// *************************************************************************** *
// *                                                                           *
// * Description:         CANDB File                                           *
// * Generated at:        2023-01-05 13:51                                     *
// * System:              FLRsystem_MAIN_26                                    *
// * Network:             FLR1CAN                                              *
// *                                                                           *
// *************************************************************************** *
VERSION "FLR1CAN"

NS_ :

BS_ :

BU_ :  FLR FLRdpHPA FLRdpHPB

BO_ 1794 Flr1canTimeSyncFr01 : 8 FLRdpHPA

BO_ 512 FlrdpFlr1canFr02 : 48 FLRdpHPA
 SG_ VehicleMotionState_UB : 280|1@0+ (1,0) [0|1] "" FLR
 SG_ VehicleMotionStateAcceleroMeterLateral : 24|15@1+ (0.0085,-138.992) [-138.992|139.00050000000002] "m/s^2" FLR
 SG_ VehicleMotionStateAccelerometerLateralQuality : 232|3@1+ (1,0) [0|7] "" FLR
 SG_ VehicleMotionStateAccelerometerLongitudinal : 40|15@1+ (0.0085,-138.992) [-138.992|139.00050000000002] "m/s^2" FLR
 SG_ VehicleMotionStateAccelerometerLongitudinalQuality : 235|3@1+ (1,0) [0|7] "" FLR
 SG_ VehicleMotionStateAccelerometerVertical : 56|15@1+ (0.0085,-138.992) [-138.992|139.00050000000002] "m/s^2" FLR
 SG_ VehicleMotionStateAccelerometerVerticalQuality : 240|3@1+ (1,0) [0|7] "" FLR
 SG_ VehicleMotionStateAngularVelocityRoll : 72|16@1+ (0.000159791,-5.236031488) [-5.236031488|5.235871697] "rad/s" FLR
 SG_ VehicleMotionStateAngularVelocityRollQuality : 243|3@1+ (1,0) [0|7] "" FLR
 SG_ VehicleMotionStateAngularVelocityYaw : 104|16@1+ (0.000159791,-5.236031488) [-5.236031488|5.235871697] "rad/s" FLR
 SG_ VehicleMotionStateAngularVelocityYawQuality : 248|3@1+ (1,0) [0|7] "" FLR
 SG_ VehicleMotionStateCounter : 16|8@1+ (1.0,0.0) [0.0|255.0] "Unitless" FLR
 SG_ VehicleMotionStateCRC : 0|16@1+ (1.0,0.0) [0.0|65535.0] "Unitless" FLR
 SG_ VehicleMotionStateMovingDirection : 251|3@1+ (1,0) [0|7] "" FLR
 SG_ VehicleMotionStateMovingDirectionQuality : 256|3@1+ (1,0) [0|7] "" FLR
 SG_ VehicleMotionStateVelocityLongitudinal : 152|13@1- (0.02,0.0) [-81.9|81.9] "m/s" FLR
 SG_ VehicleMotionStateVelocityLongitudinalQuality : 128|3@1+ (1,0) [0|7] "" FLR
 SG_ VehicleMotionStateWheelAngle : 136|15@1+ (0.00005249,-0.85) [-0.85|0.8500461200000001] "rad" FLR
 SG_ VehicleMotionStateWheelAngleQuality : 131|3@1+ (1,0) [0|7] "" FLR
 SG_ VehicleMotionStateWheelAngularVelocityFrontLeft : 168|16@1+ (0.0078125,-255.0) [-255.0|255.0] "rad/s" FLR
 SG_ VehicleMotionStateWheelAngularVelocityFrontLeftQuality : 264|3@1+ (1,0) [0|7] "" FLR
 SG_ VehicleMotionStateWheelAngularVelocityFrontRight : 184|16@1+ (0.0078125,-255.0) [-255.0|255.0] "rad/s" FLR
 SG_ VehicleMotionStateWheelAngularVelocityFrontRightQuality : 267|3@1+ (1,0) [0|7] "" FLR
 SG_ VehicleMotionStateWheelAngularVelocityRearLeft : 200|16@1+ (0.0078125,-255.0) [-255.0|255.0] "rad/s" FLR
 SG_ VehicleMotionStateWheelAngularVelocityRearLeftQuality : 272|3@1+ (1,0) [0|7] "" FLR
 SG_ VehicleMotionStateWheelAngularVelocityRearRight : 216|16@1+ (0.0078125,-255.0) [-255.0|255.0] "rad/s" FLR
 SG_ VehicleMotionStateWheelAngularVelocityRearRightQuality : 275|3@1+ (1,0) [0|7] "" FLR

BO_ 528 FlrdpFlr1canFr03 : 12 FLRdpHPA
 SG_ CarConfig_UB : 72|1@0+ (1,0) [0|1] "" FLR
 SG_ CarConfigCounter : 16|8@1+ (1.0,0.0) [0.0|255.0] "Unitless" FLR
 SG_ CarConfigCRC : 0|16@1+ (1.0,0.0) [0.0|65535.0] "Unitless" FLR
 SG_ CarConfigPropulsionType : 24|2@1+ (1,0) [0|3] "" FLR
 SG_ CarConfigVehicleTyp : 27|8@1+ (1,0) [0|255] "" FLR
 SG_ PowerModeFLR_UB : 73|1@0+ (1,0) [0|1] "" FLR
 SG_ PowerModeFLRCounter : 56|8@1+ (1.0,0.0) [0.0|255.0] "Unitless" FLR
 SG_ PowerModeFLRCRC : 40|16@1+ (1.0,0.0) [0.0|65535.0] "Unitless" FLR
 SG_ PowerModeFLRRdrActvnReq : 64|1@1+ (1,0) [0|1] "" FLR
 SG_ PowerModeFLRRdrPwrlossNoti : 65|1@1+ (1,0) [0|1] "" FLR

BO_ 544 FlrdpFlr1canFr04 : 32 FLRdpHPA
 SG_ GlobalSnapShotRdr_UB : 128|1@0+ (1,0) [0|1] "" FLR
 SG_ GlobalSnapShotRdrCounter : 16|8@1+ (1.0,0.0) [0.0|255.0] "Unitless" FLR
 SG_ GlobalSnapShotRdrCRC : 0|16@1+ (1.0,0.0) [0.0|65535.0] "Unitless" FLR
 SG_ GlobalSnapShotRdrGlobalRealTimeRdr : 24|32@1+ (1.0,0.0) [0.0|4294967295.0] "s" FLR
 SG_ GlobalSnapShotRdrOutsideTemperatureRdr : 56|16@1- (0.1,0.0) [-3276.8|3276.7000000000003] "degC" FLR
 SG_ GlobalSnapShotRdrTotalDistanceRdr : 72|32@1+ (1.0,0.0) [0.0|4294967295.0] "km" FLR
 SG_ GlobalSnapShotRdrUsageModeRdr : 104|8@1+ (1.0,0.0) [0.0|255.0] "Unitless" FLR
 SG_ GlobalSnapShotRdrVehicleBatteryVoltageRdr : 112|8@1+ (0.25,0.0) [0.0|63.75] "Volt" FLR
 SG_ GlobalSnapShotRdrVehicleSpeedRdr : 120|8@1+ (1.0,0.0) [0.0|255.0] "Km/h" FLR

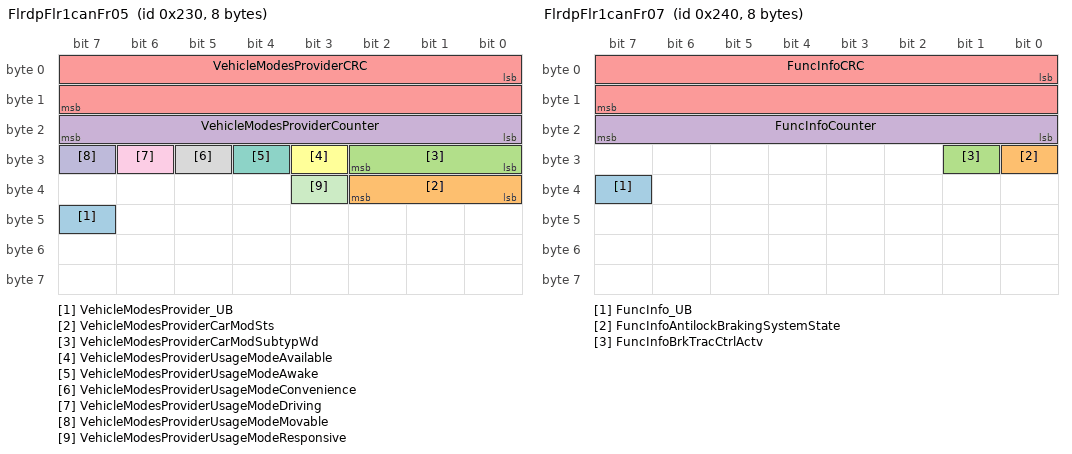
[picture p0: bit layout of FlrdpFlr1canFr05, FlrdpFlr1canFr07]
BO_ 560 FlrdpFlr1canFr05 : 8 FLRdpHPA
 SG_ VehicleModesProvider_UB : 47|1@0+ (1,0) [0|1] "" FLR
 SG_ VehicleModesProviderCarModSts : 32|3@1+ (1,0) [0|7] "" FLR
 SG_ VehicleModesProviderCarModSubtypWd : 24|3@1+ (1,0) [0|7] "" FLR
 SG_ VehicleModesProviderCounter : 16|8@1+ (1.0,0.0) [0.0|255.0] "Unitless" FLR
 SG_ VehicleModesProviderCRC : 0|16@1+ (1.0,0.0) [0.0|65535.0] "Unitless" FLR
 SG_ VehicleModesProviderUsageModeAvailable : 27|1@1+ (1,0) [0|1] "" FLR
 SG_ VehicleModesProviderUsageModeAwake : 28|1@1+ (1,0) [0|1] "" FLR
 SG_ VehicleModesProviderUsageModeConvenience : 29|1@1+ (1,0) [0|1] "" FLR
 SG_ VehicleModesProviderUsageModeDriving : 30|1@1+ (1,0) [0|1] "" FLR
 SG_ VehicleModesProviderUsageModeMovable : 31|1@1+ (1,0) [0|1] "" FLR
 SG_ VehicleModesProviderUsageModeResponsive : 35|1@1+ (1,0) [0|1] "" FLR

BO_ 576 FlrdpFlr1canFr07 : 8 FLRdpHPA
 SG_ FuncInfo_UB : 39|1@0+ (1,0) [0|1] "" FLR
 SG_ FuncInfoAntilockBrakingSystemState : 24|1@1+ (1,0) [0|1] "" FLR
 SG_ FuncInfoBrkTracCtrlActv : 25|1@1+ (1,0) [0|1] "" FLR
 SG_ FuncInfoCounter : 16|8@1+ (1.0,0.0) [0.0|255.0] "Unitless" FLR
 SG_ FuncInfoCRC : 0|16@1+ (1.0,0.0) [0.0|65535.0] "Unitless" FLR

BO_ 320 FlrFlr1canFr81 : 64 FLR
 SG_ FLR2RdrObject0To1_UB : 367|1@0+ (1,0) [0|1] "" FLRdpHPA,FLRdpHPB
 SG_ FLR2RdrObject0To1Class0 : 36|2@1+ (1,0) [0|3] "" FLRdpHPA,FLRdpHPB
 SG_ FLR2RdrObject0To1Class1 : 195|2@1+ (1,0) [0|3] "" FLRdpHPA,FLRdpHPB
 SG_ FLR2RdrObject0To1Counter : 16|8@1+ (1.0,0.0) [0.0|255.0] "Unitless" FLRdpHPA,FLRdpHPB
 SG_ FLR2RdrObject0To1CRC : 0|16@1+ (1.0,0.0) [0.0|65535.0] "Unitless" FLRdpHPA,FLRdpHPB
 SG_ FLR2RdrObject0To1DataCoastCntr0 : 38|3@1+ (1,0) [0|7] "" FLRdpHPA,FLRdpHPB
 SG_ FLR2RdrObject0To1DataCoastCntr1 : 197|3@1+ (1,0) [0|7] "" FLRdpHPA,FLRdpHPB
 SG_ FLR2RdrObject0To1DataConf0 : 41|7@1+ (1.0,0.0) [0.0|100.0] "%" FLRdpHPA,FLRdpHPB
 SG_ FLR2RdrObject0To1DataConf1 : 200|7@1+ (1.0,0.0) [0.0|100.0] "%" FLRdpHPA,FLRdpHPB
 SG_ FLR2RdrObject0To1DataLen0 : 48|8@1+ (0.2,0.0) [0.0|30.0] "m" FLRdpHPA,FLRdpHPB
 SG_ FLR2RdrObject0To1DataLen1 : 207|8@1+ (0.2,0.0) [0.0|30.0] "m" FLRdpHPA,FLRdpHPB
 SG_ FLR2RdrObject0To1DataStDLatAcc0 : 56|5@1+ (0.35,0.0) [0.0|10.85] "m/s^2" FLRdpHPA,FLRdpHPB
 SG_ FLR2RdrObject0To1DataStDLatAcc1 : 215|5@1+ (0.35,0.0) [0.0|10.85] "m/s^2" FLRdpHPA,FLRdpHPB
 SG_ FLR2RdrObject0To1DataStDLatPos0 : 61|8@1+ (0.1,0.0) [0.0|25.5] "m" FLRdpHPA,FLRdpHPB
 SG_ FLR2RdrObject0To1DataStDLatPos1 : 220|8@1+ (0.1,0.0) [0.0|25.5] "m" FLRdpHPA,FLRdpHPB
 SG_ FLR2RdrObject0To1DataStDLatVelo0 : 69|6@1+ (0.2,0.0) [0.0|12.600000000000001] "m/s" FLRdpHPA,FLRdpHPB
 SG_ FLR2RdrObject0To1DataStDLatVelo1 : 228|6@1+ (0.2,0.0) [0.0|12.600000000000001] "m/s" FLRdpHPA,FLRdpHPB
 SG_ FLR2RdrObject0To1DataStDLgtAcc0 : 75|5@1+ (0.35,0.0) [0.0|10.85] "m/s^2" FLRdpHPA,FLRdpHPB
 SG_ FLR2RdrObject0To1DataStDLgtAcc1 : 234|5@1+ (0.35,0.0) [0.0|10.85] "m/s^2" FLRdpHPA,FLRdpHPB
 SG_ FLR2RdrObject0To1DataStDLgtPos0 : 80|8@1+ (0.05,0.0) [0.0|12.75] "m" FLRdpHPA,FLRdpHPB
 SG_ FLR2RdrObject0To1DataStDLgtPos1 : 239|8@1+ (0.05,0.0) [0.0|12.75] "m" FLRdpHPA,FLRdpHPB
 SG_ FLR2RdrObject0To1DataStDLgtVelo0 : 88|6@1+ (0.2,0.0) [0.0|12.600000000000001] "m/s" FLRdpHPA,FLRdpHPB
 SG_ FLR2RdrObject0To1DataStDLgtVelo1 : 247|6@1+ (0.2,0.0) [0.0|12.600000000000001] "m/s" FLRdpHPA,FLRdpHPB
 SG_ FLR2RdrObject0To1DataWidth0 : 94|7@1+ (0.2,0.0) [0.0|15.0] "m" FLRdpHPA,FLRdpHPB
 SG_ FLR2RdrObject0To1DataWidth1 : 253|7@1+ (0.2,0.0) [0.0|15.0] "m" FLRdpHPA,FLRdpHPB
 SG_ FLR2RdrObject0To1HeadingAng0 : 101|10@1+ (0.01,-3.15) [-3.15|3.15] "rad" FLRdpHPA,FLRdpHPB
 SG_ FLR2RdrObject0To1HeadingAng1 : 260|10@1+ (0.01,-3.15) [-3.15|3.15] "rad" FLRdpHPA,FLRdpHPB
 SG_ FLR2RdrObject0To1LatAcc0 : 111|10@1+ (0.125,-44.5) [-44.5|44.5] "m/s^2" FLRdpHPA,FLRdpHPB
 SG_ FLR2RdrObject0To1LatAcc1 : 270|10@1+ (0.125,-44.5) [-44.5|44.5] "m/s^2" FLRdpHPA,FLRdpHPB
 SG_ FLR2RdrObject0To1LatPos0 : 121|13@1+ (0.0625,-255.9375) [-255.9375|255.9375] "Unitless" FLRdpHPA,FLRdpHPB
 SG_ FLR2RdrObject0To1LatPos1 : 280|13@1+ (0.0625,-255.9375) [-255.9375|255.9375] "Unitless" FLRdpHPA,FLRdpHPB
 SG_ FLR2RdrObject0To1LatVelo0 : 134|11@1+ (0.125,-128.0) [-128.0|127.875] "m/s" FLRdpHPA,FLRdpHPB
 SG_ FLR2RdrObject0To1LatVelo1 : 293|11@1+ (0.125,-128.0) [-128.0|127.875] "m/s" FLRdpHPA,FLRdpHPB
 SG_ FLR2RdrObject0To1LgtAcc0 : 145|10@1+ (0.125,-44.5) [-44.5|44.5] "m/s^2" FLRdpHPA,FLRdpHPB
 SG_ FLR2RdrObject0To1LgtAcc1 : 304|10@1+ (0.125,-44.5) [-44.5|44.5] "m/s^2" FLRdpHPA,FLRdpHPB
 SG_ FLR2RdrObject0To1LgtPos0 : 155|13@1+ (0.0625,-255.9375) [-255.9375|255.9375] "Unitless" FLRdpHPA,FLRdpHPB
 SG_ FLR2RdrObject0To1LgtPos1 : 314|13@1+ (0.0625,-255.9375) [-255.9375|255.9375] "Unitless" FLRdpHPA,FLRdpHPB
 SG_ FLR2RdrObject0To1LgtVelo0 : 168|11@1+ (0.125,-128.0) [-128.0|127.875] "m/s" FLRdpHPA,FLRdpHPB
 SG_ FLR2RdrObject0To1LgtVelo1 : 327|11@1+ (0.125,-128.0) [-128.0|127.875] "m/s" FLRdpHPA,FLRdpHPB
 SG_ FLR2RdrObject0To1ModeInfo0 : 179|2@1+ (1,0) [0|3] "" FLRdpHPA,FLRdpHPB
 SG_ FLR2RdrObject0To1ModeInfo1 : 338|2@1+ (1,0) [0|3] "" FLRdpHPA,FLRdpHPB
 SG_ FLR2RdrObject0To1MsgCntr : 32|4@1+ (1.0,0.0) [0.0|15.0] "Unitless" FLRdpHPA,FLRdpHPB
 SG_ FLR2RdrObject0To1MtnModel0 : 181|2@1+ (1.0,0.0) [0.0|3.0] "Unitless" FLRdpHPA,FLRdpHPB
 SG_ FLR2RdrObject0To1MtnModel1 : 340|2@1+ (1.0,0.0) [0.0|3.0] "Unitless" FLRdpHPA,FLRdpHPB
 SG_ FLR2RdrObject0To1MtnPattern0 : 183|4@1+ (1,0) [0|15] "" FLRdpHPA,FLRdpHPB
 SG_ FLR2RdrObject0To1MtnPattern1 : 342|4@1+ (1,0) [0|15] "" FLRdpHPA,FLRdpHPB
 SG_ FLR2RdrObject0To1PedMicroDoppler0 : 187|1@1+ (1.0,0.0) [0.0|1.0] "Unitless" FLRdpHPA,FLRdpHPB
 SG_ FLR2RdrObject0To1PedMicroDoppler1 : 346|1@1+ (1.0,0.0) [0.0|1.0] "Unitless" FLRdpHPA,FLRdpHPB
 SG_ FLR2RdrObject0To1Qly0 : 188|7@1+ (1.0,0.0) [0.0|100.0] "Unitless" FLRdpHPA,FLRdpHPB
 SG_ FLR2RdrObject0To1Qly1 : 347|7@1+ (1.0,0.0) [0.0|100.0] "Unitless" FLRdpHPA,FLRdpHPB
 SG_ FLR2RdrObject0To1ScanID : 24|8@1+ (1.0,0.0) [0.0|255.0] "Unitless" FLRdpHPA,FLRdpHPB

BO_ 322 FlrFlr1canFr82 : 64 FLR
 SG_ FLR2RdrObject2To3_UB : 367|1@0+ (1,0) [0|1] "" FLRdpHPA,FLRdpHPB
 SG_ FLR2RdrObject2To3Class0 : 36|2@1+ (1,0) [0|3] "" FLRdpHPA,FLRdpHPB
 SG_ FLR2RdrObject2To3Class1 : 195|2@1+ (1,0) [0|3] "" FLRdpHPA,FLRdpHPB
 SG_ FLR2RdrObject2To3Counter : 16|8@1+ (1.0,0.0) [0.0|255.0] "Unitless" FLRdpHPA,FLRdpHPB
 SG_ FLR2RdrObject2To3CRC : 0|16@1+ (1.0,0.0) [0.0|65535.0] "Unitless" FLRdpHPA,FLRdpHPB
 SG_ FLR2RdrObject2To3DataCoastCntr0 : 38|3@1+ (1,0) [0|7] "" FLRdpHPA,FLRdpHPB
 SG_ FLR2RdrObject2To3DataCoastCntr1 : 197|3@1+ (1,0) [0|7] "" FLRdpHPA,FLRdpHPB
 SG_ FLR2RdrObject2To3DataConf0 : 41|7@1+ (1.0,0.0) [0.0|100.0] "%" FLRdpHPA,FLRdpHPB
 SG_ FLR2RdrObject2To3DataConf1 : 200|7@1+ (1.0,0.0) [0.0|100.0] "%" FLRdpHPA,FLRdpHPB
 SG_ FLR2RdrObject2To3DataLen0 : 48|8@1+ (0.2,0.0) [0.0|30.0] "m" FLRdpHPA,FLRdpHPB
 SG_ FLR2RdrObject2To3DataLen1 : 207|8@1+ (0.2,0.0) [0.0|30.0] "m" FLRdpHPA,FLRdpHPB
 SG_ FLR2RdrObject2To3DataStDLatAcc0 : 56|5@1+ (0.35,0.0) [0.0|10.85] "m/s^2" FLRdpHPA,FLRdpHPB
 SG_ FLR2RdrObject2To3DataStDLatAcc1 : 215|5@1+ (0.35,0.0) [0.0|10.85] "m/s^2" FLRdpHPA,FLRdpHPB
 SG_ FLR2RdrObject2To3DataStDLatPos0 : 61|8@1+ (0.1,0.0) [0.0|25.5] "m" FLRdpHPA,FLRdpHPB
 SG_ FLR2RdrObject2To3DataStDLatPos1 : 220|8@1+ (0.1,0.0) [0.0|25.5] "m" FLRdpHPA,FLRdpHPB
 SG_ FLR2RdrObject2To3DataStDLatVelo0 : 69|6@1+ (0.2,0.0) [0.0|12.600000000000001] "m/s" FLRdpHPA,FLRdpHPB
 SG_ FLR2RdrObject2To3DataStDLatVelo1 : 228|6@1+ (0.2,0.0) [0.0|12.600000000000001] "m/s" FLRdpHPA,FLRdpHPB
 SG_ FLR2RdrObject2To3DataStDLgtAcc0 : 75|5@1+ (0.35,0.0) [0.0|10.85] "m/s^2" FLRdpHPA,FLRdpHPB
 SG_ FLR2RdrObject2To3DataStDLgtAcc1 : 234|5@1+ (0.35,0.0) [0.0|10.85] "m/s^2" FLRdpHPA,FLRdpHPB
 SG_ FLR2RdrObject2To3DataStDLgtPos0 : 80|8@1+ (0.05,0.0) [0.0|12.75] "m" FLRdpHPA,FLRdpHPB
 SG_ FLR2RdrObject2To3DataStDLgtPos1 : 239|8@1+ (0.05,0.0) [0.0|12.75] "m" FLRdpHPA,FLRdpHPB
 SG_ FLR2RdrObject2To3DataStDLgtVelo0 : 88|6@1+ (0.2,0.0) [0.0|12.600000000000001] "m/s" FLRdpHPA,FLRdpHPB
 SG_ FLR2RdrObject2To3DataStDLgtVelo1 : 247|6@1+ (0.2,0.0) [0.0|12.600000000000001] "m/s" FLRdpHPA,FLRdpHPB
 SG_ FLR2RdrObject2To3DataWidth0 : 94|7@1+ (0.2,0.0) [0.0|15.0] "m" FLRdpHPA,FLRdpHPB
 SG_ FLR2RdrObject2To3DataWidth1 : 253|7@1+ (0.2,0.0) [0.0|15.0] "m" FLRdpHPA,FLRdpHPB
 SG_ FLR2RdrObject2To3HeadingAng0 : 101|10@1+ (0.01,-3.15) [-3.15|3.15] "rad" FLRdpHPA,FLRdpHPB
 SG_ FLR2RdrObject2To3HeadingAng1 : 260|10@1+ (0.01,-3.15) [-3.15|3.15] "rad" FLRdpHPA,FLRdpHPB
 SG_ FLR2RdrObject2To3LatAcc0 : 111|10@1+ (0.125,-44.5) [-44.5|44.5] "m/s^2" FLRdpHPA,FLRdpHPB
 SG_ FLR2RdrObject2To3LatAcc1 : 270|10@1+ (0.125,-44.5) [-44.5|44.5] "m/s^2" FLRdpHPA,FLRdpHPB
 SG_ FLR2RdrObject2To3LatPos0 : 121|13@1+ (0.0625,-255.9375) [-255.9375|255.9375] "Unitless" FLRdpHPA,FLRdpHPB
 SG_ FLR2RdrObject2To3LatPos1 : 280|13@1+ (0.0625,-255.9375) [-255.9375|255.9375] "Unitless" FLRdpHPA,FLRdpHPB
 SG_ FLR2RdrObject2To3LatVelo0 : 134|11@1+ (0.125,-128.0) [-128.0|127.875] "m/s" FLRdpHPA,FLRdpHPB
 SG_ FLR2RdrObject2To3LatVelo1 : 293|11@1+ (0.125,-128.0) [-128.0|127.875] "m/s" FLRdpHPA,FLRdpHPB
 SG_ FLR2RdrObject2To3LgtAcc0 : 145|10@1+ (0.125,-44.5) [-44.5|44.5] "m/s^2" FLRdpHPA,FLRdpHPB
 SG_ FLR2RdrObject2To3LgtAcc1 : 304|10@1+ (0.125,-44.5) [-44.5|44.5] "m/s^2" FLRdpHPA,FLRdpHPB
 SG_ FLR2RdrObject2To3LgtPos0 : 155|13@1+ (0.0625,-255.9375) [-255.9375|255.9375] "Unitless" FLRdpHPA,FLRdpHPB
 SG_ FLR2RdrObject2To3LgtPos1 : 314|13@1+ (0.0625,-255.9375) [-255.9375|255.9375] "Unitless" FLRdpHPA,FLRdpHPB
 SG_ FLR2RdrObject2To3LgtVelo0 : 168|11@1+ (0.125,-128.0) [-128.0|127.875] "m/s" FLRdpHPA,FLRdpHPB
 SG_ FLR2RdrObject2To3LgtVelo1 : 327|11@1+ (0.125,-128.0) [-128.0|127.875] "m/s" FLRdpHPA,FLRdpHPB
 SG_ FLR2RdrObject2To3ModeInfo0 : 179|2@1+ (1,0) [0|3] "" FLRdpHPA,FLRdpHPB
 SG_ FLR2RdrObject2To3ModeInfo1 : 338|2@1+ (1,0) [0|3] "" FLRdpHPA,FLRdpHPB
 SG_ FLR2RdrObject2To3MsgCntr : 32|4@1+ (1.0,0.0) [0.0|15.0] "Unitless" FLRdpHPA,FLRdpHPB
 SG_ FLR2RdrObject2To3MtnModel0 : 181|2@1+ (1.0,0.0) [0.0|3.0] "Unitless" FLRdpHPA,FLRdpHPB
 SG_ FLR2RdrObject2To3MtnModel1 : 340|2@1+ (1.0,0.0) [0.0|3.0] "Unitless" FLRdpHPA,FLRdpHPB
 SG_ FLR2RdrObject2To3MtnPattern0 : 183|4@1+ (1,0) [0|15] "" FLRdpHPA,FLRdpHPB
 SG_ FLR2RdrObject2To3MtnPattern1 : 342|4@1+ (1,0) [0|15] "" FLRdpHPA,FLRdpHPB
 SG_ FLR2RdrObject2To3PedMicroDoppler0 : 187|1@1+ (1.0,0.0) [0.0|1.0] "Unitless" FLRdpHPA,FLRdpHPB
 SG_ FLR2RdrObject2To3PedMicroDoppler1 : 346|1@1+ (1.0,0.0) [0.0|1.0] "Unitless" FLRdpHPA,FLRdpHPB
 SG_ FLR2RdrObject2To3Qly0 : 188|7@1+ (1.0,0.0) [0.0|100.0] "Unitless" FLRdpHPA,FLRdpHPB
 SG_ FLR2RdrObject2To3Qly1 : 347|7@1+ (1.0,0.0) [0.0|100.0] "Unitless" FLRdpHPA,FLRdpHPB
 SG_ FLR2RdrObject2To3ScanID : 24|8@1+ (1.0,0.0) [0.0|255.0] "Unitless" FLRdpHPA,FLRdpHPB

BO_ 324 FlrFlr1canFr83 : 64 FLR
 SG_ FLR2RdrObject4To5_UB : 367|1@0+ (1,0) [0|1] "" FLRdpHPA,FLRdpHPB
 SG_ FLR2RdrObject4To5Class0 : 36|2@1+ (1,0) [0|3] "" FLRdpHPA,FLRdpHPB
 SG_ FLR2RdrObject4To5Class1 : 195|2@1+ (1,0) [0|3] "" FLRdpHPA,FLRdpHPB
 SG_ FLR2RdrObject4To5Counter : 16|8@1+ (1.0,0.0) [0.0|255.0] "Unitless" FLRdpHPA,FLRdpHPB
 SG_ FLR2RdrObject4To5CRC : 0|16@1+ (1.0,0.0) [0.0|65535.0] "Unitless" FLRdpHPA,FLRdpHPB
 SG_ FLR2RdrObject4To5DataCoastCntr0 : 38|3@1+ (1,0) [0|7] "" FLRdpHPA,FLRdpHPB
 SG_ FLR2RdrObject4To5DataCoastCntr1 : 197|3@1+ (1,0) [0|7] "" FLRdpHPA,FLRdpHPB
 SG_ FLR2RdrObject4To5DataConf0 : 41|7@1+ (1.0,0.0) [0.0|100.0] "%" FLRdpHPA,FLRdpHPB
 SG_ FLR2RdrObject4To5DataConf1 : 200|7@1+ (1.0,0.0) [0.0|100.0] "%" FLRdpHPA,FLRdpHPB
 SG_ FLR2RdrObject4To5DataLen0 : 48|8@1+ (0.2,0.0) [0.0|30.0] "m" FLRdpHPA,FLRdpHPB
 SG_ FLR2RdrObject4To5DataLen1 : 207|8@1+ (0.2,0.0) [0.0|30.0] "m" FLRdpHPA,FLRdpHPB
 SG_ FLR2RdrObject4To5DataStDLatAcc0 : 56|5@1+ (0.35,0.0) [0.0|10.85] "m/s^2" FLRdpHPA,FLRdpHPB
 SG_ FLR2RdrObject4To5DataStDLatAcc1 : 215|5@1+ (0.35,0.0) [0.0|10.85] "m/s^2" FLRdpHPA,FLRdpHPB
 SG_ FLR2RdrObject4To5DataStDLatPos0 : 61|8@1+ (0.1,0.0) [0.0|25.5] "m" FLRdpHPA,FLRdpHPB
 SG_ FLR2RdrObject4To5DataStDLatPos1 : 220|8@1+ (0.1,0.0) [0.0|25.5] "m" FLRdpHPA,FLRdpHPB
 SG_ FLR2RdrObject4To5DataStDLatVelo0 : 69|6@1+ (0.2,0.0) [0.0|12.600000000000001] "m/s" FLRdpHPA,FLRdpHPB
 SG_ FLR2RdrObject4To5DataStDLatVelo1 : 228|6@1+ (0.2,0.0) [0.0|12.600000000000001] "m/s" FLRdpHPA,FLRdpHPB
 SG_ FLR2RdrObject4To5DataStDLgtAcc0 : 75|5@1+ (0.35,0.0) [0.0|10.85] "m/s^2" FLRdpHPA,FLRdpHPB
 SG_ FLR2RdrObject4To5DataStDLgtAcc1 : 234|5@1+ (0.35,0.0) [0.0|10.85] "m/s^2" FLRdpHPA,FLRdpHPB
 SG_ FLR2RdrObject4To5DataStDLgtPos0 : 80|8@1+ (0.05,0.0) [0.0|12.75] "m" FLRdpHPA,FLRdpHPB
 SG_ FLR2RdrObject4To5DataStDLgtPos1 : 239|8@1+ (0.05,0.0) [0.0|12.75] "m" FLRdpHPA,FLRdpHPB
 SG_ FLR2RdrObject4To5DataStDLgtVelo0 : 88|6@1+ (0.2,0.0) [0.0|12.600000000000001] "m/s" FLRdpHPA,FLRdpHPB
 SG_ FLR2RdrObject4To5DataStDLgtVelo1 : 247|6@1+ (0.2,0.0) [0.0|12.600000000000001] "m/s" FLRdpHPA,FLRdpHPB
 SG_ FLR2RdrObject4To5DataWidth0 : 94|7@1+ (0.2,0.0) [0.0|15.0] "m" FLRdpHPA,FLRdpHPB
 SG_ FLR2RdrObject4To5DataWidth1 : 253|7@1+ (0.2,0.0) [0.0|15.0] "m" FLRdpHPA,FLRdpHPB
 SG_ FLR2RdrObject4To5HeadingAng0 : 101|10@1+ (0.01,-3.15) [-3.15|3.15] "rad" FLRdpHPA,FLRdpHPB
 SG_ FLR2RdrObject4To5HeadingAng1 : 260|10@1+ (0.01,-3.15) [-3.15|3.15] "rad" FLRdpHPA,FLRdpHPB
 SG_ FLR2RdrObject4To5LatAcc0 : 111|10@1+ (0.125,-44.5) [-44.5|44.5] "m/s^2" FLRdpHPA,FLRdpHPB
 SG_ FLR2RdrObject4To5LatAcc1 : 270|10@1+ (0.125,-44.5) [-44.5|44.5] "m/s^2" FLRdpHPA,FLRdpHPB
 SG_ FLR2RdrObject4To5LatPos0 : 121|13@1+ (0.0625,-255.9375) [-255.9375|255.9375] "Unitless" FLRdpHPA,FLRdpHPB
 SG_ FLR2RdrObject4To5LatPos1 : 280|13@1+ (0.0625,-255.9375) [-255.9375|255.9375] "Unitless" FLRdpHPA,FLRdpHPB
 SG_ FLR2RdrObject4To5LatVelo0 : 134|11@1+ (0.125,-128.0) [-128.0|127.875] "m/s" FLRdpHPA,FLRdpHPB
 SG_ FLR2RdrObject4To5LatVelo1 : 293|11@1+ (0.125,-128.0) [-128.0|127.875] "m/s" FLRdpHPA,FLRdpHPB
 SG_ FLR2RdrObject4To5LgtAcc0 : 145|10@1+ (0.125,-44.5) [-44.5|44.5] "m/s^2" FLRdpHPA,FLRdpHPB
 SG_ FLR2RdrObject4To5LgtAcc1 : 304|10@1+ (0.125,-44.5) [-44.5|44.5] "m/s^2" FLRdpHPA,FLRdpHPB
 SG_ FLR2RdrObject4To5LgtPos0 : 155|13@1+ (0.0625,-255.9375) [-255.9375|255.9375] "Unitless" FLRdpHPA,FLRdpHPB
 SG_ FLR2RdrObject4To5LgtPos1 : 314|13@1+ (0.0625,-255.9375) [-255.9375|255.9375] "Unitless" FLRdpHPA,FLRdpHPB
 SG_ FLR2RdrObject4To5LgtVelo0 : 168|11@1+ (0.125,-128.0) [-128.0|127.875] "m/s" FLRdpHPA,FLRdpHPB
 SG_ FLR2RdrObject4To5LgtVelo1 : 327|11@1+ (0.125,-128.0) [-128.0|127.875] "m/s" FLRdpHPA,FLRdpHPB
 SG_ FLR2RdrObject4To5ModeInfo0 : 179|2@1+ (1,0) [0|3] "" FLRdpHPA,FLRdpHPB
 SG_ FLR2RdrObject4To5ModeInfo1 : 338|2@1+ (1,0) [0|3] "" FLRdpHPA,FLRdpHPB
 SG_ FLR2RdrObject4To5MsgCntr : 32|4@1+ (1.0,0.0) [0.0|15.0] "Unitless" FLRdpHPA,FLRdpHPB
 SG_ FLR2RdrObject4To5MtnModel0 : 181|2@1+ (1.0,0.0) [0.0|3.0] "Unitless" FLRdpHPA,FLRdpHPB
 SG_ FLR2RdrObject4To5MtnModel1 : 340|2@1+ (1.0,0.0) [0.0|3.0] "Unitless" FLRdpHPA,FLRdpHPB
 SG_ FLR2RdrObject4To5MtnPattern0 : 183|4@1+ (1,0) [0|15] "" FLRdpHPA,FLRdpHPB
 SG_ FLR2RdrObject4To5MtnPattern1 : 342|4@1+ (1,0) [0|15] "" FLRdpHPA,FLRdpHPB
 SG_ FLR2RdrObject4To5PedMicroDoppler0 : 187|1@1+ (1.0,0.0) [0.0|1.0] "Unitless" FLRdpHPA,FLRdpHPB
 SG_ FLR2RdrObject4To5PedMicroDoppler1 : 346|1@1+ (1.0,0.0) [0.0|1.0] "Unitless" FLRdpHPA,FLRdpHPB
 SG_ FLR2RdrObject4To5Qly0 : 188|7@1+ (1.0,0.0) [0.0|100.0] "Unitless" FLRdpHPA,FLRdpHPB
 SG_ FLR2RdrObject4To5Qly1 : 347|7@1+ (1.0,0.0) [0.0|100.0] "Unitless" FLRdpHPA,FLRdpHPB
 SG_ FLR2RdrObject4To5ScanID : 24|8@1+ (1.0,0.0) [0.0|255.0] "Unitless" FLRdpHPA,FLRdpHPB

BO_ 326 FlrFlr1canFr84 : 64 FLR
 SG_ FLR2RdrObject6To7_UB : 367|1@0+ (1,0) [0|1] "" FLRdpHPA,FLRdpHPB
 SG_ FLR2RdrObject6To7Class0 : 36|2@1+ (1,0) [0|3] "" FLRdpHPA,FLRdpHPB
 SG_ FLR2RdrObject6To7Class1 : 195|2@1+ (1,0) [0|3] "" FLRdpHPA,FLRdpHPB
 SG_ FLR2RdrObject6To7Counter : 16|8@1+ (1.0,0.0) [0.0|255.0] "Unitless" FLRdpHPA,FLRdpHPB
 SG_ FLR2RdrObject6To7CRC : 0|16@1+ (1.0,0.0) [0.0|65535.0] "Unitless" FLRdpHPA,FLRdpHPB
 SG_ FLR2RdrObject6To7DataCoastCntr0 : 38|3@1+ (1,0) [0|7] "" FLRdpHPA,FLRdpHPB
 SG_ FLR2RdrObject6To7DataCoastCntr1 : 197|3@1+ (1,0) [0|7] "" FLRdpHPA,FLRdpHPB
 SG_ FLR2RdrObject6To7DataConf0 : 41|7@1+ (1.0,0.0) [0.0|100.0] "%" FLRdpHPA,FLRdpHPB
 SG_ FLR2RdrObject6To7DataConf1 : 200|7@1+ (1.0,0.0) [0.0|100.0] "%" FLRdpHPA,FLRdpHPB
 SG_ FLR2RdrObject6To7DataLen0 : 48|8@1+ (0.2,0.0) [0.0|30.0] "m" FLRdpHPA,FLRdpHPB
 SG_ FLR2RdrObject6To7DataLen1 : 207|8@1+ (0.2,0.0) [0.0|30.0] "m" FLRdpHPA,FLRdpHPB
 SG_ FLR2RdrObject6To7DataStDLatAcc0 : 56|5@1+ (0.35,0.0) [0.0|10.85] "m/s^2" FLRdpHPA,FLRdpHPB
 SG_ FLR2RdrObject6To7DataStDLatAcc1 : 215|5@1+ (0.35,0.0) [0.0|10.85] "m/s^2" FLRdpHPA,FLRdpHPB
 SG_ FLR2RdrObject6To7DataStDLatPos0 : 61|8@1+ (0.1,0.0) [0.0|25.5] "m" FLRdpHPA,FLRdpHPB
 SG_ FLR2RdrObject6To7DataStDLatPos1 : 220|8@1+ (0.1,0.0) [0.0|25.5] "m" FLRdpHPA,FLRdpHPB
 SG_ FLR2RdrObject6To7DataStDLatVelo0 : 69|6@1+ (0.2,0.0) [0.0|12.600000000000001] "m/s" FLRdpHPA,FLRdpHPB
 SG_ FLR2RdrObject6To7DataStDLatVelo1 : 228|6@1+ (0.2,0.0) [0.0|12.600000000000001] "m/s" FLRdpHPA,FLRdpHPB
 SG_ FLR2RdrObject6To7DataStDLgtAcc0 : 75|5@1+ (0.35,0.0) [0.0|10.85] "m/s^2" FLRdpHPA,FLRdpHPB
 SG_ FLR2RdrObject6To7DataStDLgtAcc1 : 234|5@1+ (0.35,0.0) [0.0|10.85] "m/s^2" FLRdpHPA,FLRdpHPB
 SG_ FLR2RdrObject6To7DataStDLgtPos0 : 80|8@1+ (0.05,0.0) [0.0|12.75] "m" FLRdpHPA,FLRdpHPB
 SG_ FLR2RdrObject6To7DataStDLgtPos1 : 239|8@1+ (0.05,0.0) [0.0|12.75] "m" FLRdpHPA,FLRdpHPB
 SG_ FLR2RdrObject6To7DataStDLgtVelo0 : 88|6@1+ (0.2,0.0) [0.0|12.600000000000001] "m/s" FLRdpHPA,FLRdpHPB
 SG_ FLR2RdrObject6To7DataStDLgtVelo1 : 247|6@1+ (0.2,0.0) [0.0|12.600000000000001] "m/s" FLRdpHPA,FLRdpHPB
 SG_ FLR2RdrObject6To7DataWidth0 : 94|7@1+ (0.2,0.0) [0.0|15.0] "m" FLRdpHPA,FLRdpHPB
 SG_ FLR2RdrObject6To7DataWidth1 : 253|7@1+ (0.2,0.0) [0.0|15.0] "m" FLRdpHPA,FLRdpHPB
 SG_ FLR2RdrObject6To7HeadingAng0 : 101|10@1+ (0.01,-3.15) [-3.15|3.15] "rad" FLRdpHPA,FLRdpHPB
 SG_ FLR2RdrObject6To7HeadingAng1 : 260|10@1+ (0.01,-3.15) [-3.15|3.15] "rad" FLRdpHPA,FLRdpHPB
 SG_ FLR2RdrObject6To7LatAcc0 : 111|10@1+ (0.125,-44.5) [-44.5|44.5] "m/s^2" FLRdpHPA,FLRdpHPB
 SG_ FLR2RdrObject6To7LatAcc1 : 270|10@1+ (0.125,-44.5) [-44.5|44.5] "m/s^2" FLRdpHPA,FLRdpHPB
 SG_ FLR2RdrObject6To7LatPos0 : 121|13@1+ (0.0625,-255.9375) [-255.9375|255.9375] "Unitless" FLRdpHPA,FLRdpHPB
 SG_ FLR2RdrObject6To7LatPos1 : 280|13@1+ (0.0625,-255.9375) [-255.9375|255.9375] "Unitless" FLRdpHPA,FLRdpHPB
 SG_ FLR2RdrObject6To7LatVelo0 : 134|11@1+ (0.125,-128.0) [-128.0|127.875] "m/s" FLRdpHPA,FLRdpHPB
 SG_ FLR2RdrObject6To7LatVelo1 : 293|11@1+ (0.125,-128.0) [-128.0|127.875] "m/s" FLRdpHPA,FLRdpHPB
 SG_ FLR2RdrObject6To7LgtAcc0 : 145|10@1+ (0.125,-44.5) [-44.5|44.5] "m/s^2" FLRdpHPA,FLRdpHPB
 SG_ FLR2RdrObject6To7LgtAcc1 : 304|10@1+ (0.125,-44.5) [-44.5|44.5] "m/s^2" FLRdpHPA,FLRdpHPB
 SG_ FLR2RdrObject6To7LgtPos0 : 155|13@1+ (0.0625,-255.9375) [-255.9375|255.9375] "Unitless" FLRdpHPA,FLRdpHPB
 SG_ FLR2RdrObject6To7LgtPos1 : 314|13@1+ (0.0625,-255.9375) [-255.9375|255.9375] "Unitless" FLRdpHPA,FLRdpHPB
 SG_ FLR2RdrObject6To7LgtVelo0 : 168|11@1+ (0.125,-128.0) [-128.0|127.875] "m/s" FLRdpHPA,FLRdpHPB
 SG_ FLR2RdrObject6To7LgtVelo1 : 327|11@1+ (0.125,-128.0) [-128.0|127.875] "m/s" FLRdpHPA,FLRdpHPB
 SG_ FLR2RdrObject6To7ModeInfo0 : 179|2@1+ (1,0) [0|3] "" FLRdpHPA,FLRdpHPB
 SG_ FLR2RdrObject6To7ModeInfo1 : 338|2@1+ (1,0) [0|3] "" FLRdpHPA,FLRdpHPB
 SG_ FLR2RdrObject6To7MsgCntr : 32|4@1+ (1.0,0.0) [0.0|15.0] "Unitless" FLRdpHPA,FLRdpHPB
 SG_ FLR2RdrObject6To7MtnModel0 : 181|2@1+ (1.0,0.0) [0.0|3.0] "Unitless" FLRdpHPA,FLRdpHPB
 SG_ FLR2RdrObject6To7MtnModel1 : 340|2@1+ (1.0,0.0) [0.0|3.0] "Unitless" FLRdpHPA,FLRdpHPB
 SG_ FLR2RdrObject6To7MtnPattern0 : 183|4@1+ (1,0) [0|15] "" FLRdpHPA,FLRdpHPB
 SG_ FLR2RdrObject6To7MtnPattern1 : 342|4@1+ (1,0) [0|15] "" FLRdpHPA,FLRdpHPB
 SG_ FLR2RdrObject6To7PedMicroDoppler0 : 187|1@1+ (1.0,0.0) [0.0|1.0] "Unitless" FLRdpHPA,FLRdpHPB
 SG_ FLR2RdrObject6To7PedMicroDoppler1 : 346|1@1+ (1.0,0.0) [0.0|1.0] "Unitless" FLRdpHPA,FLRdpHPB
 SG_ FLR2RdrObject6To7Qly0 : 188|7@1+ (1.0,0.0) [0.0|100.0] "Unitless" FLRdpHPA,FLRdpHPB
 SG_ FLR2RdrObject6To7Qly1 : 347|7@1+ (1.0,0.0) [0.0|100.0] "Unitless" FLRdpHPA,FLRdpHPB
 SG_ FLR2RdrObject6To7ScanID : 24|8@1+ (1.0,0.0) [0.0|255.0] "Unitless" FLRdpHPA,FLRdpHPB

BO_ 328 FlrFlr1canFr85 : 64 FLR
 SG_ FLR2RdrObject8To9_UB : 367|1@0+ (1,0) [0|1] "" FLRdpHPA,FLRdpHPB
 SG_ FLR2RdrObject8To9Class0 : 36|2@1+ (1,0) [0|3] "" FLRdpHPA,FLRdpHPB
 SG_ FLR2RdrObject8To9Class1 : 195|2@1+ (1,0) [0|3] "" FLRdpHPA,FLRdpHPB
 SG_ FLR2RdrObject8To9Counter : 16|8@1+ (1.0,0.0) [0.0|255.0] "Unitless" FLRdpHPA,FLRdpHPB
 SG_ FLR2RdrObject8To9CRC : 0|16@1+ (1.0,0.0) [0.0|65535.0] "Unitless" FLRdpHPA,FLRdpHPB
 SG_ FLR2RdrObject8To9DataCoastCntr0 : 38|3@1+ (1,0) [0|7] "" FLRdpHPA,FLRdpHPB
 SG_ FLR2RdrObject8To9DataCoastCntr1 : 197|3@1+ (1,0) [0|7] "" FLRdpHPA,FLRdpHPB
 SG_ FLR2RdrObject8To9DataConf0 : 41|7@1+ (1.0,0.0) [0.0|100.0] "%" FLRdpHPA,FLRdpHPB
 SG_ FLR2RdrObject8To9DataConf1 : 200|7@1+ (1.0,0.0) [0.0|100.0] "%" FLRdpHPA,FLRdpHPB
 SG_ FLR2RdrObject8To9DataLen0 : 48|8@1+ (0.2,0.0) [0.0|30.0] "m" FLRdpHPA,FLRdpHPB
 SG_ FLR2RdrObject8To9DataLen1 : 207|8@1+ (0.2,0.0) [0.0|30.0] "m" FLRdpHPA,FLRdpHPB
 SG_ FLR2RdrObject8To9DataStDLatAcc0 : 56|5@1+ (0.35,0.0) [0.0|10.85] "m/s^2" FLRdpHPA,FLRdpHPB
 SG_ FLR2RdrObject8To9DataStDLatAcc1 : 215|5@1+ (0.35,0.0) [0.0|10.85] "m/s^2" FLRdpHPA,FLRdpHPB
 SG_ FLR2RdrObject8To9DataStDLatPos0 : 61|8@1+ (0.1,0.0) [0.0|25.5] "m" FLRdpHPA,FLRdpHPB
 SG_ FLR2RdrObject8To9DataStDLatPos1 : 220|8@1+ (0.1,0.0) [0.0|25.5] "m" FLRdpHPA,FLRdpHPB
 SG_ FLR2RdrObject8To9DataStDLatVelo0 : 69|6@1+ (0.2,0.0) [0.0|12.600000000000001] "m/s" FLRdpHPA,FLRdpHPB
 SG_ FLR2RdrObject8To9DataStDLatVelo1 : 228|6@1+ (0.2,0.0) [0.0|12.600000000000001] "m/s" FLRdpHPA,FLRdpHPB
 SG_ FLR2RdrObject8To9DataStDLgtAcc0 : 75|5@1+ (0.35,0.0) [0.0|10.85] "m/s^2" FLRdpHPA,FLRdpHPB
 SG_ FLR2RdrObject8To9DataStDLgtAcc1 : 234|5@1+ (0.35,0.0) [0.0|10.85] "m/s^2" FLRdpHPA,FLRdpHPB
 SG_ FLR2RdrObject8To9DataStDLgtPos0 : 80|8@1+ (0.05,0.0) [0.0|12.75] "m" FLRdpHPA,FLRdpHPB
 SG_ FLR2RdrObject8To9DataStDLgtPos1 : 239|8@1+ (0.05,0.0) [0.0|12.75] "m" FLRdpHPA,FLRdpHPB
 SG_ FLR2RdrObject8To9DataStDLgtVelo0 : 88|6@1+ (0.2,0.0) [0.0|12.600000000000001] "m/s" FLRdpHPA,FLRdpHPB
 SG_ FLR2RdrObject8To9DataStDLgtVelo1 : 247|6@1+ (0.2,0.0) [0.0|12.600000000000001] "m/s" FLRdpHPA,FLRdpHPB
 SG_ FLR2RdrObject8To9DataWidth0 : 94|7@1+ (0.2,0.0) [0.0|15.0] "m" FLRdpHPA,FLRdpHPB
 SG_ FLR2RdrObject8To9DataWidth1 : 253|7@1+ (0.2,0.0) [0.0|15.0] "m" FLRdpHPA,FLRdpHPB
 SG_ FLR2RdrObject8To9HeadingAng0 : 101|10@1+ (0.01,-3.15) [-3.15|3.15] "rad" FLRdpHPA,FLRdpHPB
 SG_ FLR2RdrObject8To9HeadingAng1 : 260|10@1+ (0.01,-3.15) [-3.15|3.15] "rad" FLRdpHPA,FLRdpHPB
 SG_ FLR2RdrObject8To9LatAcc0 : 111|10@1+ (0.125,-44.5) [-44.5|44.5] "m/s^2" FLRdpHPA,FLRdpHPB
 SG_ FLR2RdrObject8To9LatAcc1 : 270|10@1+ (0.125,-44.5) [-44.5|44.5] "m/s^2" FLRdpHPA,FLRdpHPB
 SG_ FLR2RdrObject8To9LatPos0 : 121|13@1+ (0.0625,-255.9375) [-255.9375|255.9375] "Unitless" FLRdpHPA,FLRdpHPB
 SG_ FLR2RdrObject8To9LatPos1 : 280|13@1+ (0.0625,-255.9375) [-255.9375|255.9375] "Unitless" FLRdpHPA,FLRdpHPB
 SG_ FLR2RdrObject8To9LatVelo0 : 134|11@1+ (0.125,-128.0) [-128.0|127.875] "m/s" FLRdpHPA,FLRdpHPB
 SG_ FLR2RdrObject8To9LatVelo1 : 293|11@1+ (0.125,-128.0) [-128.0|127.875] "m/s" FLRdpHPA,FLRdpHPB
 SG_ FLR2RdrObject8To9LgtAcc0 : 145|10@1+ (0.125,-44.5) [-44.5|44.5] "m/s^2" FLRdpHPA,FLRdpHPB
 SG_ FLR2RdrObject8To9LgtAcc1 : 304|10@1+ (0.125,-44.5) [-44.5|44.5] "m/s^2" FLRdpHPA,FLRdpHPB
 SG_ FLR2RdrObject8To9LgtPos0 : 155|13@1+ (0.0625,-255.9375) [-255.9375|255.9375] "Unitless" FLRdpHPA,FLRdpHPB
 SG_ FLR2RdrObject8To9LgtPos1 : 314|13@1+ (0.0625,-255.9375) [-255.9375|255.9375] "Unitless" FLRdpHPA,FLRdpHPB
 SG_ FLR2RdrObject8To9LgtVelo0 : 168|11@1+ (0.125,-128.0) [-128.0|127.875] "m/s" FLRdpHPA,FLRdpHPB
 SG_ FLR2RdrObject8To9LgtVelo1 : 327|11@1+ (0.125,-128.0) [-128.0|127.875] "m/s" FLRdpHPA,FLRdpHPB
 SG_ FLR2RdrObject8To9ModeInfo0 : 179|2@1+ (1,0) [0|3] "" FLRdpHPA,FLRdpHPB
 SG_ FLR2RdrObject8To9ModeInfo1 : 338|2@1+ (1,0) [0|3] "" FLRdpHPA,FLRdpHPB
 SG_ FLR2RdrObject8To9MsgCntr : 32|4@1+ (1.0,0.0) [0.0|15.0] "Unitless" FLRdpHPA,FLRdpHPB
 SG_ FLR2RdrObject8To9MtnModel0 : 181|2@1+ (1.0,0.0) [0.0|3.0] "Unitless" FLRdpHPA,FLRdpHPB
 SG_ FLR2RdrObject8To9MtnModel1 : 340|2@1+ (1.0,0.0) [0.0|3.0] "Unitless" FLRdpHPA,FLRdpHPB
 SG_ FLR2RdrObject8To9MtnPattern0 : 183|4@1+ (1,0) [0|15] "" FLRdpHPA,FLRdpHPB
 SG_ FLR2RdrObject8To9MtnPattern1 : 342|4@1+ (1,0) [0|15] "" FLRdpHPA,FLRdpHPB
 SG_ FLR2RdrObject8To9PedMicroDoppler0 : 187|1@1+ (1.0,0.0) [0.0|1.0] "Unitless" FLRdpHPA,FLRdpHPB
 SG_ FLR2RdrObject8To9PedMicroDoppler1 : 346|1@1+ (1.0,0.0) [0.0|1.0] "Unitless" FLRdpHPA,FLRdpHPB
 SG_ FLR2RdrObject8To9Qly0 : 188|7@1+ (1.0,0.0) [0.0|100.0] "Unitless" FLRdpHPA,FLRdpHPB
 SG_ FLR2RdrObject8To9Qly1 : 347|7@1+ (1.0,0.0) [0.0|100.0] "Unitless" FLRdpHPA,FLRdpHPB
 SG_ FLR2RdrObject8To9ScanID : 24|8@1+ (1.0,0.0) [0.0|255.0] "Unitless" FLRdpHPA,FLRdpHPB

BO_ 330 FlrFlr1canFr86 : 64 FLR
 SG_ FLR2RdrObject10To11_UB : 367|1@0+ (1,0) [0|1] "" FLRdpHPA,FLRdpHPB
 SG_ FLR2RdrObject10To11Class0 : 36|2@1+ (1,0) [0|3] "" FLRdpHPA,FLRdpHPB
 SG_ FLR2RdrObject10To11Class1 : 195|2@1+ (1,0) [0|3] "" FLRdpHPA,FLRdpHPB
 SG_ FLR2RdrObject10To11Counter : 16|8@1+ (1.0,0.0) [0.0|255.0] "Unitless" FLRdpHPA,FLRdpHPB
 SG_ FLR2RdrObject10To11CRC : 0|16@1+ (1.0,0.0) [0.0|65535.0] "Unitless" FLRdpHPA,FLRdpHPB
 SG_ FLR2RdrObject10To11DataCoastCntr0 : 38|3@1+ (1,0) [0|7] "" FLRdpHPA,FLRdpHPB
 SG_ FLR2RdrObject10To11DataCoastCntr1 : 197|3@1+ (1,0) [0|7] "" FLRdpHPA,FLRdpHPB
 SG_ FLR2RdrObject10To11DataConf0 : 41|7@1+ (1.0,0.0) [0.0|100.0] "%" FLRdpHPA,FLRdpHPB
 SG_ FLR2RdrObject10To11DataConf1 : 200|7@1+ (1.0,0.0) [0.0|100.0] "%" FLRdpHPA,FLRdpHPB
 SG_ FLR2RdrObject10To11DataLen0 : 48|8@1+ (0.2,0.0) [0.0|30.0] "m" FLRdpHPA,FLRdpHPB
 SG_ FLR2RdrObject10To11DataLen1 : 207|8@1+ (0.2,0.0) [0.0|30.0] "m" FLRdpHPA,FLRdpHPB
 SG_ FLR2RdrObject10To11DataStDLatAcc0 : 56|5@1+ (0.35,0.0) [0.0|10.85] "m/s^2" FLRdpHPA,FLRdpHPB
 SG_ FLR2RdrObject10To11DataStDLatAcc1 : 215|5@1+ (0.35,0.0) [0.0|10.85] "m/s^2" FLRdpHPA,FLRdpHPB
 SG_ FLR2RdrObject10To11DataStDLatPos0 : 61|8@1+ (0.1,0.0) [0.0|25.5] "m" FLRdpHPA,FLRdpHPB
 SG_ FLR2RdrObject10To11DataStDLatPos1 : 220|8@1+ (0.1,0.0) [0.0|25.5] "m" FLRdpHPA,FLRdpHPB
 SG_ FLR2RdrObject10To11DataStDLatVelo0 : 69|6@1+ (0.2,0.0) [0.0|12.600000000000001] "m/s" FLRdpHPA,FLRdpHPB
 SG_ FLR2RdrObject10To11DataStDLatVelo1 : 228|6@1+ (0.2,0.0) [0.0|12.600000000000001] "m/s" FLRdpHPA,FLRdpHPB
 SG_ FLR2RdrObject10To11DataStDLgtAcc0 : 75|5@1+ (0.35,0.0) [0.0|10.85] "m/s^2" FLRdpHPA,FLRdpHPB
 SG_ FLR2RdrObject10To11DataStDLgtAcc1 : 234|5@1+ (0.35,0.0) [0.0|10.85] "m/s^2" FLRdpHPA,FLRdpHPB
 SG_ FLR2RdrObject10To11DataStDLgtPos0 : 80|8@1+ (0.05,0.0) [0.0|12.75] "m" FLRdpHPA,FLRdpHPB
 SG_ FLR2RdrObject10To11DataStDLgtPos1 : 239|8@1+ (0.05,0.0) [0.0|12.75] "m" FLRdpHPA,FLRdpHPB
 SG_ FLR2RdrObject10To11DataStDLgtVelo0 : 88|6@1+ (0.2,0.0) [0.0|12.600000000000001] "m/s" FLRdpHPA,FLRdpHPB
 SG_ FLR2RdrObject10To11DataStDLgtVelo1 : 247|6@1+ (0.2,0.0) [0.0|12.600000000000001] "m/s" FLRdpHPA,FLRdpHPB
 SG_ FLR2RdrObject10To11DataWidth0 : 94|7@1+ (0.2,0.0) [0.0|15.0] "m" FLRdpHPA,FLRdpHPB
 SG_ FLR2RdrObject10To11DataWidth1 : 253|7@1+ (0.2,0.0) [0.0|15.0] "m" FLRdpHPA,FLRdpHPB
 SG_ FLR2RdrObject10To11HeadingAng0 : 101|10@1+ (0.01,-3.15) [-3.15|3.15] "rad" FLRdpHPA,FLRdpHPB
 SG_ FLR2RdrObject10To11HeadingAng1 : 260|10@1+ (0.01,-3.15) [-3.15|3.15] "rad" FLRdpHPA,FLRdpHPB
 SG_ FLR2RdrObject10To11LatAcc0 : 111|10@1+ (0.125,-44.5) [-44.5|44.5] "m/s^2" FLRdpHPA,FLRdpHPB
 SG_ FLR2RdrObject10To11LatAcc1 : 270|10@1+ (0.125,-44.5) [-44.5|44.5] "m/s^2" FLRdpHPA,FLRdpHPB
 SG_ FLR2RdrObject10To11LatPos0 : 121|13@1+ (0.0625,-255.9375) [-255.9375|255.9375] "Unitless" FLRdpHPA,FLRdpHPB
 SG_ FLR2RdrObject10To11LatPos1 : 280|13@1+ (0.0625,-255.9375) [-255.9375|255.9375] "Unitless" FLRdpHPA,FLRdpHPB
 SG_ FLR2RdrObject10To11LatVelo0 : 134|11@1+ (0.125,-128.0) [-128.0|127.875] "m/s" FLRdpHPA,FLRdpHPB
 SG_ FLR2RdrObject10To11LatVelo1 : 293|11@1+ (0.125,-128.0) [-128.0|127.875] "m/s" FLRdpHPA,FLRdpHPB
 SG_ FLR2RdrObject10To11LgtAcc0 : 145|10@1+ (0.125,-44.5) [-44.5|44.5] "m/s^2" FLRdpHPA,FLRdpHPB
 SG_ FLR2RdrObject10To11LgtAcc1 : 304|10@1+ (0.125,-44.5) [-44.5|44.5] "m/s^2" FLRdpHPA,FLRdpHPB
 SG_ FLR2RdrObject10To11LgtPos0 : 155|13@1+ (0.0625,-255.9375) [-255.9375|255.9375] "Unitless" FLRdpHPA,FLRdpHPB
 SG_ FLR2RdrObject10To11LgtPos1 : 314|13@1+ (0.0625,-255.9375) [-255.9375|255.9375] "Unitless" FLRdpHPA,FLRdpHPB
 SG_ FLR2RdrObject10To11LgtVelo0 : 168|11@1+ (0.125,-128.0) [-128.0|127.875] "m/s" FLRdpHPA,FLRdpHPB
 SG_ FLR2RdrObject10To11LgtVelo1 : 327|11@1+ (0.125,-128.0) [-128.0|127.875] "m/s" FLRdpHPA,FLRdpHPB
 SG_ FLR2RdrObject10To11ModeInfo0 : 179|2@1+ (1,0) [0|3] "" FLRdpHPA,FLRdpHPB
 SG_ FLR2RdrObject10To11ModeInfo1 : 338|2@1+ (1,0) [0|3] "" FLRdpHPA,FLRdpHPB
 SG_ FLR2RdrObject10To11MsgCntr : 32|4@1+ (1.0,0.0) [0.0|15.0] "Unitless" FLRdpHPA,FLRdpHPB
 SG_ FLR2RdrObject10To11MtnModel0 : 181|2@1+ (1.0,0.0) [0.0|3.0] "Unitless" FLRdpHPA,FLRdpHPB
 SG_ FLR2RdrObject10To11MtnModel1 : 340|2@1+ (1.0,0.0) [0.0|3.0] "Unitless" FLRdpHPA,FLRdpHPB
 SG_ FLR2RdrObject10To11MtnPattern0 : 183|4@1+ (1,0) [0|15] "" FLRdpHPA,FLRdpHPB
 SG_ FLR2RdrObject10To11MtnPattern1 : 342|4@1+ (1,0) [0|15] "" FLRdpHPA,FLRdpHPB
 SG_ FLR2RdrObject10To11PedMicroDoppler0 : 187|1@1+ (1.0,0.0) [0.0|1.0] "Unitless" FLRdpHPA,FLRdpHPB
 SG_ FLR2RdrObject10To11PedMicroDoppler1 : 346|1@1+ (1.0,0.0) [0.0|1.0] "Unitless" FLRdpHPA,FLRdpHPB
 SG_ FLR2RdrObject10To11Qly0 : 188|7@1+ (1.0,0.0) [0.0|100.0] "Unitless" FLRdpHPA,FLRdpHPB
 SG_ FLR2RdrObject10To11Qly1 : 347|7@1+ (1.0,0.0) [0.0|100.0] "Unitless" FLRdpHPA,FLRdpHPB
 SG_ FLR2RdrObject10To11ScanID : 24|8@1+ (1.0,0.0) [0.0|255.0] "Unitless" FLRdpHPA,FLRdpHPB

BO_ 332 FlrFlr1canFr87 : 64 FLR
 SG_ FLR2RdrObject12To13_UB : 367|1@0+ (1,0) [0|1] "" FLRdpHPA,FLRdpHPB
 SG_ FLR2RdrObject12To13Class0 : 36|2@1+ (1,0) [0|3] "" FLRdpHPA,FLRdpHPB
 SG_ FLR2RdrObject12To13Class1 : 195|2@1+ (1,0) [0|3] "" FLRdpHPA,FLRdpHPB
 SG_ FLR2RdrObject12To13Counter : 16|8@1+ (1.0,0.0) [0.0|255.0] "Unitless" FLRdpHPA,FLRdpHPB
 SG_ FLR2RdrObject12To13CRC : 0|16@1+ (1.0,0.0) [0.0|65535.0] "Unitless" FLRdpHPA,FLRdpHPB
 SG_ FLR2RdrObject12To13DataCoastCntr0 : 38|3@1+ (1,0) [0|7] "" FLRdpHPA,FLRdpHPB
 SG_ FLR2RdrObject12To13DataCoastCntr1 : 197|3@1+ (1,0) [0|7] "" FLRdpHPA,FLRdpHPB
 SG_ FLR2RdrObject12To13DataConf0 : 41|7@1+ (1.0,0.0) [0.0|100.0] "%" FLRdpHPA,FLRdpHPB
 SG_ FLR2RdrObject12To13DataConf1 : 200|7@1+ (1.0,0.0) [0.0|100.0] "%" FLRdpHPA,FLRdpHPB
 SG_ FLR2RdrObject12To13DataLen0 : 48|8@1+ (0.2,0.0) [0.0|30.0] "m" FLRdpHPA,FLRdpHPB
 SG_ FLR2RdrObject12To13DataLen1 : 207|8@1+ (0.2,0.0) [0.0|30.0] "m" FLRdpHPA,FLRdpHPB
 SG_ FLR2RdrObject12To13DataStDLatAcc0 : 56|5@1+ (0.35,0.0) [0.0|10.85] "m/s^2" FLRdpHPA,FLRdpHPB
 SG_ FLR2RdrObject12To13DataStDLatAcc1 : 215|5@1+ (0.35,0.0) [0.0|10.85] "m/s^2" FLRdpHPA,FLRdpHPB
 SG_ FLR2RdrObject12To13DataStDLatPos0 : 61|8@1+ (0.1,0.0) [0.0|25.5] "m" FLRdpHPA,FLRdpHPB
 SG_ FLR2RdrObject12To13DataStDLatPos1 : 220|8@1+ (0.1,0.0) [0.0|25.5] "m" FLRdpHPA,FLRdpHPB
 SG_ FLR2RdrObject12To13DataStDLatVelo0 : 69|6@1+ (0.2,0.0) [0.0|12.600000000000001] "m/s" FLRdpHPA,FLRdpHPB
 SG_ FLR2RdrObject12To13DataStDLatVelo1 : 228|6@1+ (0.2,0.0) [0.0|12.600000000000001] "m/s" FLRdpHPA,FLRdpHPB
 SG_ FLR2RdrObject12To13DataStDLgtAcc0 : 75|5@1+ (0.35,0.0) [0.0|10.85] "m/s^2" FLRdpHPA,FLRdpHPB
 SG_ FLR2RdrObject12To13DataStDLgtAcc1 : 234|5@1+ (0.35,0.0) [0.0|10.85] "m/s^2" FLRdpHPA,FLRdpHPB
 SG_ FLR2RdrObject12To13DataStDLgtPos0 : 80|8@1+ (0.05,0.0) [0.0|12.75] "m" FLRdpHPA,FLRdpHPB
 SG_ FLR2RdrObject12To13DataStDLgtPos1 : 239|8@1+ (0.05,0.0) [0.0|12.75] "m" FLRdpHPA,FLRdpHPB
 SG_ FLR2RdrObject12To13DataStDLgtVelo0 : 88|6@1+ (0.2,0.0) [0.0|12.600000000000001] "m/s" FLRdpHPA,FLRdpHPB
 SG_ FLR2RdrObject12To13DataStDLgtVelo1 : 247|6@1+ (0.2,0.0) [0.0|12.600000000000001] "m/s" FLRdpHPA,FLRdpHPB
 SG_ FLR2RdrObject12To13DataWidth0 : 94|7@1+ (0.2,0.0) [0.0|15.0] "m" FLRdpHPA,FLRdpHPB
 SG_ FLR2RdrObject12To13DataWidth1 : 253|7@1+ (0.2,0.0) [0.0|15.0] "m" FLRdpHPA,FLRdpHPB
 SG_ FLR2RdrObject12To13HeadingAng0 : 101|10@1+ (0.01,-3.15) [-3.15|3.15] "rad" FLRdpHPA,FLRdpHPB
 SG_ FLR2RdrObject12To13HeadingAng1 : 260|10@1+ (0.01,-3.15) [-3.15|3.15] "rad" FLRdpHPA,FLRdpHPB
 SG_ FLR2RdrObject12To13LatAcc0 : 111|10@1+ (0.125,-44.5) [-44.5|44.5] "m/s^2" FLRdpHPA,FLRdpHPB
 SG_ FLR2RdrObject12To13LatAcc1 : 270|10@1+ (0.125,-44.5) [-44.5|44.5] "m/s^2" FLRdpHPA,FLRdpHPB
 SG_ FLR2RdrObject12To13LatPos0 : 121|13@1+ (0.0625,-255.9375) [-255.9375|255.9375] "Unitless" FLRdpHPA,FLRdpHPB
 SG_ FLR2RdrObject12To13LatPos1 : 280|13@1+ (0.0625,-255.9375) [-255.9375|255.9375] "Unitless" FLRdpHPA,FLRdpHPB
 SG_ FLR2RdrObject12To13LatVelo0 : 134|11@1+ (0.125,-128.0) [-128.0|127.875] "m/s" FLRdpHPA,FLRdpHPB
 SG_ FLR2RdrObject12To13LatVelo1 : 293|11@1+ (0.125,-128.0) [-128.0|127.875] "m/s" FLRdpHPA,FLRdpHPB
 SG_ FLR2RdrObject12To13LgtAcc0 : 145|10@1+ (0.125,-44.5) [-44.5|44.5] "m/s^2" FLRdpHPA,FLRdpHPB
 SG_ FLR2RdrObject12To13LgtAcc1 : 304|10@1+ (0.125,-44.5) [-44.5|44.5] "m/s^2" FLRdpHPA,FLRdpHPB
 SG_ FLR2RdrObject12To13LgtPos0 : 155|13@1+ (0.0625,-255.9375) [-255.9375|255.9375] "Unitless" FLRdpHPA,FLRdpHPB
 SG_ FLR2RdrObject12To13LgtPos1 : 314|13@1+ (0.0625,-255.9375) [-255.9375|255.9375] "Unitless" FLRdpHPA,FLRdpHPB
 SG_ FLR2RdrObject12To13LgtVelo0 : 168|11@1+ (0.125,-128.0) [-128.0|127.875] "m/s" FLRdpHPA,FLRdpHPB
 SG_ FLR2RdrObject12To13LgtVelo1 : 327|11@1+ (0.125,-128.0) [-128.0|127.875] "m/s" FLRdpHPA,FLRdpHPB
 SG_ FLR2RdrObject12To13ModeInfo0 : 179|2@1+ (1,0) [0|3] "" FLRdpHPA,FLRdpHPB
 SG_ FLR2RdrObject12To13ModeInfo1 : 338|2@1+ (1,0) [0|3] "" FLRdpHPA,FLRdpHPB
 SG_ FLR2RdrObject12To13MsgCntr : 32|4@1+ (1.0,0.0) [0.0|15.0] "Unitless" FLRdpHPA,FLRdpHPB
 SG_ FLR2RdrObject12To13MtnModel0 : 181|2@1+ (1.0,0.0) [0.0|3.0] "Unitless" FLRdpHPA,FLRdpHPB
 SG_ FLR2RdrObject12To13MtnModel1 : 340|2@1+ (1.0,0.0) [0.0|3.0] "Unitless" FLRdpHPA,FLRdpHPB
 SG_ FLR2RdrObject12To13MtnPattern0 : 183|4@1+ (1,0) [0|15] "" FLRdpHPA,FLRdpHPB
 SG_ FLR2RdrObject12To13MtnPattern1 : 342|4@1+ (1,0) [0|15] "" FLRdpHPA,FLRdpHPB
 SG_ FLR2RdrObject12To13PedMicroDoppler0 : 187|1@1+ (1.0,0.0) [0.0|1.0] "Unitless" FLRdpHPA,FLRdpHPB
 SG_ FLR2RdrObject12To13PedMicroDoppler1 : 346|1@1+ (1.0,0.0) [0.0|1.0] "Unitless" FLRdpHPA,FLRdpHPB
 SG_ FLR2RdrObject12To13Qly0 : 188|7@1+ (1.0,0.0) [0.0|100.0] "Unitless" FLRdpHPA,FLRdpHPB
 SG_ FLR2RdrObject12To13Qly1 : 347|7@1+ (1.0,0.0) [0.0|100.0] "Unitless" FLRdpHPA,FLRdpHPB
 SG_ FLR2RdrObject12To13ScanID : 24|8@1+ (1.0,0.0) [0.0|255.0] "Unitless" FLRdpHPA,FLRdpHPB

// Signal Comments
CM_ SG_ 512 VehicleMotionStateAcceleroMeterLateral "Lateral acceleration of the Inertial Measurement Unit";
CM_ SG_ 512 VehicleMotionStateAccelerometerLateralQuality "Quality Of Estimate";
CM_ SG_ 512 VehicleMotionStateAccelerometerLongitudinal "Longitudinal acceleration of the Inertial Measurement Unit";
CM_ SG_ 512 VehicleMotionStateAccelerometerLongitudinalQuality "Quality of estimate";
CM_ SG_ 512 VehicleMotionStateAccelerometerVertical "Vertical acceleration of the Inertial Measurement Unit";
CM_ SG_ 512 VehicleMotionStateAccelerometerVerticalQuality "Quality of estimate";
CM_ SG_ 512 VehicleMotionStateAngularVelocityRoll "Roll angular velocity about the x-axis. Also referred to as roll rate. Affected during start of cornering or driving into banked roads. Roll angle defined positive when banking right";
CM_ SG_ 512 VehicleMotionStateAngularVelocityRollQuality "Quality of Estimate";
CM_ SG_ 512 VehicleMotionStateAngularVelocityYaw "Yaw angular velocity about the z-axis. Also referred to as yaw rate. Affected during steering changes. Yaw angle defined positive when turning left";
CM_ SG_ 512 VehicleMotionStateAngularVelocityYawQuality "Quality Of Estimate";
CM_ SG_ 512 VehicleMotionStateCounter "Counter";
CM_ SG_ 512 VehicleMotionStateCRC "CRC";
CM_ SG_ 512 VehicleMotionStateMovingDirection "Moving direction of vehicle";
CM_ SG_ 512 VehicleMotionStateMovingDirectionQuality "Quality of Estimate";
CM_ SG_ 512 VehicleMotionStateVelocityLongitudinal "Estimate of instantanious longitudinal velocity of vehicle using wheel rotary encoders, the Inertial Measurement Unit and the Global Positioning System. Vehicle axis system defined by ISO 8855";
CM_ SG_ 512 VehicleMotionStateVelocityLongitudinalQuality "Quality of Estimate";
CM_ SG_ 512 VehicleMotionStateWheelAngle "Front steering angle estimate";
CM_ SG_ 512 VehicleMotionStateWheelAngleQuality "Quality of Estimate";
CM_ SG_ 512 VehicleMotionStateWheelAngularVelocityFrontLeft "Front left wheel angular velocity";
CM_ SG_ 512 VehicleMotionStateWheelAngularVelocityFrontLeftQuality "Quality of Estimate";
CM_ SG_ 512 VehicleMotionStateWheelAngularVelocityFrontRight "Front right wheel angular velocity";
CM_ SG_ 512 VehicleMotionStateWheelAngularVelocityFrontRightQuality "Quality of Estimate";
CM_ SG_ 512 VehicleMotionStateWheelAngularVelocityRearLeft "Rear left wheel angular velocity";
CM_ SG_ 512 VehicleMotionStateWheelAngularVelocityRearLeftQuality "Quality Of Estimate";
CM_ SG_ 512 VehicleMotionStateWheelAngularVelocityRearRight "Rear right wheel angular velocity";
CM_ SG_ 512 VehicleMotionStateWheelAngularVelocityRearRightQuality "Quality of Estimate";
CM_ SG_ 528 CarConfigVehicleTyp "CarConfiguration Parameter which states which car model the sw shall be adapted to";
CM_ SG_ 528 PowerModeFLRCounter "Counter";
CM_ SG_ 528 PowerModeFLRCRC "CRC";
CM_ SG_ 528 PowerModeFLRRdrActvnReq "Radar Activation Request";
CM_ SG_ 528 PowerModeFLRRdrPwrlossNoti "Radar Power Loss Notification";
CM_ SG_ 544 GlobalSnapShotRdrCounter "Counter";
CM_ SG_ 544 GlobalSnapShotRdrCRC "CRC";
CM_ SG_ 544 GlobalSnapShotRdrGlobalRealTimeRdr "Global Real Time";
CM_ SG_ 544 GlobalSnapShotRdrOutsideTemperatureRdr "Outside Temperature";
CM_ SG_ 544 GlobalSnapShotRdrTotalDistanceRdr "Total Distance";
CM_ SG_ 544 GlobalSnapShotRdrUsageModeRdr "Usage Mode";
CM_ SG_ 544 GlobalSnapShotRdrVehicleBatteryVoltageRdr "Vehicle Battery Voltage";
CM_ SG_ 544 GlobalSnapShotRdrVehicleSpeedRdr "Vehicle Speed";
CM_ SG_ 560 VehicleModesProviderCarModSts "Product Lifecycle distributes different lifecycle modes of the vehicle which includes Car Mode e.g. (normal, transport, dyno, factory), Crash Mode. These product lifecycle modes are not only for safety and security management but also for preserving energy resources (HV/LV). Product Lifecycle modes which includes normal, transport, factory, dyno are set based on diagnostics input, crash mode from SRS or dyno mode are triggered by driver input sequence. Detailed description how these different modes are changed can be seen in section Scope & Boundary Diagram.";
CM_ SG_ 560 VehicleModesProviderCarModSubtypWd "Normal The default subtype during normal operation.factoryPaused  When the vehicle is only temporary in carmode Normal during factory parking.FactoryDriving When the vehicle is only temporary in carmode Norval during factory driving.TransportDriving When the vehicle is only temporary in carmode Normal during transport parking.TwoWheelDyno When the user has selected two wheel dynamometer in carmode Dyno.FourWheelDyno When the user has selected four wheel dynamometer in croak Dyno.";
CM_ SG_ 560 VehicleModesProviderUsageModeResponsive "Usage Mode Responsive";
CM_ SG_ 576 FuncInfoAntilockBrakingSystemState "State of the Anti-lock braking system (ABS) for all wheels , is_enabled    bool Indicates if the ABS function is disabled due to a failure or enabled";
CM_ SG_ 576 FuncInfoBrkTracCtrlActv "Indicates  if brake traction control (TC) is active on at least one wheel";

// Attribute definitions
BA_DEF_  "BaudRateCANFD" FLOAT 1000 10000000; // [bps]
BA_DEF_  "Baudrate" INT 1000 1000000; // [bps]
BA_DEF_  "BusType" STRING;
BA_DEF_  "DBName" STRING;
BA_DEF_  "ProtocolType" STRING;
BA_DEF_ BO_ "CANFD_BRS" ENUM "0","1";
BA_DEF_ BO_ "GenMsgCycleTime" INT 0 65536; // [ms]
BA_DEF_ BO_ "GenMsgDelayTime" INT 0 65536; // [ms]
BA_DEF_ BO_ "GenMsgSendType" ENUM "cyclic", "spontaneous", "not-used", "not-used", "not-used", "cyclicAndSpontaneous", "not-used", "cyclicIfActive", "NoMsgSendType"; // [us]
BA_DEF_ BO_ "GenMsgStartDelayTime" INT 0 65536; // [ms]
BA_DEF_ BO_ "VFrameFormat" ENUM "StandardCAN","ExtendedCAN","reserved","J1939PG","reserved","reserved","reserved","reserved","reserved","reserved","reserved","reserved","reserved","reserved","StandardCAN_FD","ExtendedCAN_FD";
BA_DEF_ SG_ "GenSigSendType" ENUM "Cyclic","OnWrite","OnWriteWithRepetition","OnChange","OnChangeWithRepetition","IfActive","IfActiveWithRepetition","NoSigSendType";
BA_DEF_ SG_ "GenSigStartValue" HEX 0 80000000;
BA_DEF_ BO_ "GenMsgILSupport" ENUM "No","Yes";
BA_DEF_ BO_ "NmAsrMessage" ENUM "No","Yes";
BA_DEF_  "NmAsrBaseAddress" HEX 0 536870911;
BA_DEF_  "NmAsrMessageCount" INT 0 255;
BA_DEF_ BU_ "NodeLayerModules" STRING;
BA_DEF_ BU_ "ILused" ENUM "No","Yes";
BA_DEF_ SG_ "GenSigFuncType" ENUM "NoFunction","n/a","n/a","n/a","n/a","n/a","n/a","n/a","n/a","n/a","n/a","n/a","n/a","n/a","n/a","CHK","CNTR","n/a","n/a","n/a","CNTR_AR_01","CRC_AR_01_BOTH","CRC_AR_01_ALT","CRC_AR_01_LOW","CRC_AR_01_NIBBLE","CNTR_AR_04","CRC_AR_04A","CNTR_AR_05","CRC_AR_05";
BA_DEF_ SG_ "GenSigDataID" STRING;

BA_DEF_DEF_ "BusType" "";
BA_DEF_DEF_ "DBName" "";
BA_DEF_DEF_ "ProtocolType" "";
BA_DEF_DEF_ "CANFD_BRS" "1";
BA_DEF_DEF_ "GenSigStartValue" 0;
BA_DEF_DEF_ "VFrameFormat" "J1939PG";
BA_DEF_DEF_ "GenSigSendType" "NoSigSendType";
BA_DEF_DEF_ "GenMsgCycleTime" 0;
BA_DEF_DEF_ "GenMsgDelayTime" 0;
BA_DEF_DEF_ "GenMsgStartDelayTime" 0;
BA_DEF_DEF_ "GenMsgSendType" "NoMsgSendType";
BA_DEF_DEF_ "GenMsgILSupport" "Yes";
BA_DEF_DEF_ "NmAsrMessage" "No";
BA_DEF_DEF_ "NmAsrBaseAddress" 1280;
BA_DEF_DEF_ "NmAsrMessageCount" 64;
BA_DEF_DEF_ "NodeLayerModules" "CANoeILNLSPA.dll";
BA_DEF_DEF_ "ILused" "Yes";
BA_DEF_DEF_ "GenSigFuncType" "NoFunction";
BA_DEF_DEF_ "GenSigDataID" "";

BA_ "BaudRateCANFD" 2000000;
BA_ "Baudrate" 500000;
BA_ "BusType" "CAN FD";
BA_ "DBName" "FLR1CAN";
BA_ "ProtocolType" "CAN";
// ECU: FLR
BA_ "ILused" BU_ FLR 0;
// ECU: FLRdpHPA
BA_ "ILused" BU_ FLRdpHPA 0;
// ECU: FLRdpHPB
BA_ "ILused" BU_ FLRdpHPB 0;
// Frame: Flr1canTimeSyncFr01
BA_ "GenMsgDelayTime" BO_ 1794 50.000;
BA_ "GenMsgSendType" BO_ 1794 1;
BA_ "VFrameFormat" BO_ 1794 0;
// Frame: FlrFlr1canFr81
BA_ "GenMsgDelayTime" BO_ 320 40.000;
BA_ "GenMsgSendType" BO_ 320 1;
BA_ "VFrameFormat" BO_ 320 14;
// Frame: FlrFlr1canFr82
BA_ "GenMsgDelayTime" BO_ 322 40.000;
BA_ "GenMsgSendType" BO_ 322 1;
BA_ "VFrameFormat" BO_ 322 14;
// Frame: FlrFlr1canFr83
BA_ "GenMsgDelayTime" BO_ 324 40.000;
BA_ "GenMsgSendType" BO_ 324 1;
BA_ "VFrameFormat" BO_ 324 14;
// Frame: FlrFlr1canFr84
BA_ "GenMsgDelayTime" BO_ 326 40.000;
BA_ "GenMsgSendType" BO_ 326 1;
BA_ "VFrameFormat" BO_ 326 14;
// Frame: FlrFlr1canFr85
BA_ "GenMsgDelayTime" BO_ 328 40.000;
BA_ "GenMsgSendType" BO_ 328 1;
BA_ "VFrameFormat" BO_ 328 14;
// Frame: FlrFlr1canFr86
BA_ "GenMsgDelayTime" BO_ 330 40.000;
BA_ "GenMsgSendType" BO_ 330 1;
BA_ "VFrameFormat" BO_ 330 14;
// Frame: FlrFlr1canFr87
BA_ "GenMsgDelayTime" BO_ 332 40.000;
BA_ "GenMsgSendType" BO_ 332 1;
BA_ "VFrameFormat" BO_ 332 14;
// Frame: FlrdpFlr1canFr02
BA_ "GenMsgCycleTime" BO_ 512 60.000;
BA_ "GenMsgSendType" BO_ 512 0;
BA_ "VFrameFormat" BO_ 512 14;
// Frame: FlrdpFlr1canFr03
BA_ "GenMsgCycleTime" BO_ 528 60.000;
BA_ "GenMsgSendType" BO_ 528 0;
BA_ "VFrameFormat" BO_ 528 14;
// Frame: FlrdpFlr1canFr04
BA_ "GenMsgCycleTime" BO_ 544 60.000;
BA_ "GenMsgSendType" BO_ 544 0;
BA_ "VFrameFormat" BO_ 544 14;
// Frame: FlrdpFlr1canFr05
BA_ "GenMsgCycleTime" BO_ 560 60.000;
BA_ "GenMsgSendType" BO_ 560 0;
BA_ "VFrameFormat" BO_ 560 14;
// Frame: FlrdpFlr1canFr07
BA_ "GenMsgCycleTime" BO_ 576 60.000;
BA_ "GenMsgSendType" BO_ 576 0;
BA_ "VFrameFormat" BO_ 576 14;
BA_ "GenSigDataID" SG_ 528 CarConfigCRC "0xA35";
BA_ "GenSigFuncType" SG_ 528 CarConfigCRC 28;
BA_ "GenSigSendType" SG_ 528 CarConfigCRC 0;
BA_ "GenSigFuncType" SG_ 528 CarConfigCounter 27;
BA_ "GenSigSendType" SG_ 528 CarConfigCounter 0;
BA_ "GenSigSendType" SG_ 528 CarConfigPropulsionType 0;
BA_ "GenSigSendType" SG_ 528 CarConfigVehicleTyp 0;
BA_ "GenSigDataID" SG_ 320 FLR2RdrObject0To1CRC "0x8CE";
BA_ "GenSigFuncType" SG_ 320 FLR2RdrObject0To1CRC 28;
BA_ "GenSigSendType" SG_ 320 FLR2RdrObject0To1CRC 1;
BA_ "GenSigSendType" SG_ 320 FLR2RdrObject0To1Class0 1;
BA_ "GenSigSendType" SG_ 320 FLR2RdrObject0To1Class1 1;
BA_ "GenSigFuncType" SG_ 320 FLR2RdrObject0To1Counter 27;
BA_ "GenSigSendType" SG_ 320 FLR2RdrObject0To1Counter 1;
BA_ "GenSigSendType" SG_ 320 FLR2RdrObject0To1DataCoastCntr0 1;
BA_ "GenSigSendType" SG_ 320 FLR2RdrObject0To1DataCoastCntr1 1;
BA_ "GenSigSendType" SG_ 320 FLR2RdrObject0To1DataConf0 1;
BA_ "GenSigSendType" SG_ 320 FLR2RdrObject0To1DataConf1 1;
BA_ "GenSigSendType" SG_ 320 FLR2RdrObject0To1DataLen0 1;
BA_ "GenSigSendType" SG_ 320 FLR2RdrObject0To1DataLen1 1;
BA_ "GenSigSendType" SG_ 320 FLR2RdrObject0To1DataStDLatAcc0 1;
BA_ "GenSigSendType" SG_ 320 FLR2RdrObject0To1DataStDLatAcc1 1;
BA_ "GenSigSendType" SG_ 320 FLR2RdrObject0To1DataStDLatPos0 1;
BA_ "GenSigSendType" SG_ 320 FLR2RdrObject0To1DataStDLatPos1 1;
BA_ "GenSigSendType" SG_ 320 FLR2RdrObject0To1DataStDLatVelo0 1;
BA_ "GenSigSendType" SG_ 320 FLR2RdrObject0To1DataStDLatVelo1 1;
BA_ "GenSigSendType" SG_ 320 FLR2RdrObject0To1DataStDLgtAcc0 1;
BA_ "GenSigSendType" SG_ 320 FLR2RdrObject0To1DataStDLgtAcc1 1;
BA_ "GenSigSendType" SG_ 320 FLR2RdrObject0To1DataStDLgtPos0 1;
BA_ "GenSigSendType" SG_ 320 FLR2RdrObject0To1DataStDLgtPos1 1;
BA_ "GenSigSendType" SG_ 320 FLR2RdrObject0To1DataStDLgtVelo0 1;
BA_ "GenSigSendType" SG_ 320 FLR2RdrObject0To1DataStDLgtVelo1 1;
BA_ "GenSigSendType" SG_ 320 FLR2RdrObject0To1DataWidth0 1;
BA_ "GenSigSendType" SG_ 320 FLR2RdrObject0To1DataWidth1 1;
BA_ "GenSigSendType" SG_ 320 FLR2RdrObject0To1HeadingAng0 1;
BA_ "GenSigStartValue" SG_ 320 FLR2RdrObject0To1HeadingAng0 315;
BA_ "GenSigSendType" SG_ 320 FLR2RdrObject0To1HeadingAng1 1;
BA_ "GenSigStartValue" SG_ 320 FLR2RdrObject0To1HeadingAng1 315;
BA_ "GenSigSendType" SG_ 320 FLR2RdrObject0To1LatAcc0 1;
BA_ "GenSigStartValue" SG_ 320 FLR2RdrObject0To1LatAcc0 356;
BA_ "GenSigSendType" SG_ 320 FLR2RdrObject0To1LatAcc1 1;
BA_ "GenSigStartValue" SG_ 320 FLR2RdrObject0To1LatAcc1 356;
BA_ "GenSigSendType" SG_ 320 FLR2RdrObject0To1LatPos0 1;
BA_ "GenSigStartValue" SG_ 320 FLR2RdrObject0To1LatPos0 4095;
BA_ "GenSigSendType" SG_ 320 FLR2RdrObject0To1LatPos1 1;
BA_ "GenSigStartValue" SG_ 320 FLR2RdrObject0To1LatPos1 4095;
BA_ "GenSigSendType" SG_ 320 FLR2RdrObject0To1LatVelo0 1;
BA_ "GenSigStartValue" SG_ 320 FLR2RdrObject0To1LatVelo0 1024;
BA_ "GenSigSendType" SG_ 320 FLR2RdrObject0To1LatVelo1 1;
BA_ "GenSigStartValue" SG_ 320 FLR2RdrObject0To1LatVelo1 1024;
BA_ "GenSigSendType" SG_ 320 FLR2RdrObject0To1LgtAcc0 1;
BA_ "GenSigStartValue" SG_ 320 FLR2RdrObject0To1LgtAcc0 356;
BA_ "GenSigSendType" SG_ 320 FLR2RdrObject0To1LgtAcc1 1;
BA_ "GenSigStartValue" SG_ 320 FLR2RdrObject0To1LgtAcc1 356;
BA_ "GenSigSendType" SG_ 320 FLR2RdrObject0To1LgtPos0 1;
BA_ "GenSigStartValue" SG_ 320 FLR2RdrObject0To1LgtPos0 4095;
BA_ "GenSigSendType" SG_ 320 FLR2RdrObject0To1LgtPos1 1;
BA_ "GenSigStartValue" SG_ 320 FLR2RdrObject0To1LgtPos1 4095;
BA_ "GenSigSendType" SG_ 320 FLR2RdrObject0To1LgtVelo0 1;
BA_ "GenSigStartValue" SG_ 320 FLR2RdrObject0To1LgtVelo0 1024;
BA_ "GenSigSendType" SG_ 320 FLR2RdrObject0To1LgtVelo1 1;
BA_ "GenSigStartValue" SG_ 320 FLR2RdrObject0To1LgtVelo1 1024;
BA_ "GenSigSendType" SG_ 320 FLR2RdrObject0To1ModeInfo0 1;
BA_ "GenSigSendType" SG_ 320 FLR2RdrObject0To1ModeInfo1 1;
BA_ "GenSigSendType" SG_ 320 FLR2RdrObject0To1MsgCntr 1;
BA_ "GenSigSendType" SG_ 320 FLR2RdrObject0To1MtnModel0 1;
BA_ "GenSigSendType" SG_ 320 FLR2RdrObject0To1MtnModel1 1;
BA_ "GenSigSendType" SG_ 320 FLR2RdrObject0To1MtnPattern0 1;
BA_ "GenSigSendType" SG_ 320 FLR2RdrObject0To1MtnPattern1 1;
BA_ "GenSigSendType" SG_ 320 FLR2RdrObject0To1PedMicroDoppler0 1;
BA_ "GenSigSendType" SG_ 320 FLR2RdrObject0To1PedMicroDoppler1 1;
BA_ "GenSigSendType" SG_ 320 FLR2RdrObject0To1Qly0 1;
BA_ "GenSigSendType" SG_ 320 FLR2RdrObject0To1Qly1 1;
BA_ "GenSigSendType" SG_ 320 FLR2RdrObject0To1ScanID 1;
BA_ "GenSigDataID" SG_ 330 FLR2RdrObject10To11CRC "0x8D3";
BA_ "GenSigFuncType" SG_ 330 FLR2RdrObject10To11CRC 28;
BA_ "GenSigSendType" SG_ 330 FLR2RdrObject10To11CRC 1;
BA_ "GenSigSendType" SG_ 330 FLR2RdrObject10To11Class0 1;
BA_ "GenSigSendType" SG_ 330 FLR2RdrObject10To11Class1 1;
BA_ "GenSigFuncType" SG_ 330 FLR2RdrObject10To11Counter 27;
BA_ "GenSigSendType" SG_ 330 FLR2RdrObject10To11Counter 1;
BA_ "GenSigSendType" SG_ 330 FLR2RdrObject10To11DataCoastCntr0 1;
BA_ "GenSigSendType" SG_ 330 FLR2RdrObject10To11DataCoastCntr1 1;
BA_ "GenSigSendType" SG_ 330 FLR2RdrObject10To11DataConf0 1;
BA_ "GenSigSendType" SG_ 330 FLR2RdrObject10To11DataConf1 1;
BA_ "GenSigSendType" SG_ 330 FLR2RdrObject10To11DataLen0 1;
BA_ "GenSigSendType" SG_ 330 FLR2RdrObject10To11DataLen1 1;
BA_ "GenSigSendType" SG_ 330 FLR2RdrObject10To11DataStDLatAcc0 1;
BA_ "GenSigSendType" SG_ 330 FLR2RdrObject10To11DataStDLatAcc1 1;
BA_ "GenSigSendType" SG_ 330 FLR2RdrObject10To11DataStDLatPos0 1;
BA_ "GenSigSendType" SG_ 330 FLR2RdrObject10To11DataStDLatPos1 1;
BA_ "GenSigSendType" SG_ 330 FLR2RdrObject10To11DataStDLatVelo0 1;
BA_ "GenSigSendType" SG_ 330 FLR2RdrObject10To11DataStDLatVelo1 1;
BA_ "GenSigSendType" SG_ 330 FLR2RdrObject10To11DataStDLgtAcc0 1;
BA_ "GenSigSendType" SG_ 330 FLR2RdrObject10To11DataStDLgtAcc1 1;
BA_ "GenSigSendType" SG_ 330 FLR2RdrObject10To11DataStDLgtPos0 1;
BA_ "GenSigSendType" SG_ 330 FLR2RdrObject10To11DataStDLgtPos1 1;
BA_ "GenSigSendType" SG_ 330 FLR2RdrObject10To11DataStDLgtVelo0 1;
BA_ "GenSigSendType" SG_ 330 FLR2RdrObject10To11DataStDLgtVelo1 1;
BA_ "GenSigSendType" SG_ 330 FLR2RdrObject10To11DataWidth0 1;
BA_ "GenSigSendType" SG_ 330 FLR2RdrObject10To11DataWidth1 1;
BA_ "GenSigSendType" SG_ 330 FLR2RdrObject10To11HeadingAng0 1;
BA_ "GenSigStartValue" SG_ 330 FLR2RdrObject10To11HeadingAng0 315;
BA_ "GenSigSendType" SG_ 330 FLR2RdrObject10To11HeadingAng1 1;
BA_ "GenSigStartValue" SG_ 330 FLR2RdrObject10To11HeadingAng1 315;
BA_ "GenSigSendType" SG_ 330 FLR2RdrObject10To11LatAcc0 1;
BA_ "GenSigStartValue" SG_ 330 FLR2RdrObject10To11LatAcc0 356;
BA_ "GenSigSendType" SG_ 330 FLR2RdrObject10To11LatAcc1 1;
BA_ "GenSigStartValue" SG_ 330 FLR2RdrObject10To11LatAcc1 356;
BA_ "GenSigSendType" SG_ 330 FLR2RdrObject10To11LatPos0 1;
BA_ "GenSigStartValue" SG_ 330 FLR2RdrObject10To11LatPos0 4095;
BA_ "GenSigSendType" SG_ 330 FLR2RdrObject10To11LatPos1 1;
BA_ "GenSigStartValue" SG_ 330 FLR2RdrObject10To11LatPos1 4095;
BA_ "GenSigSendType" SG_ 330 FLR2RdrObject10To11LatVelo0 1;
BA_ "GenSigStartValue" SG_ 330 FLR2RdrObject10To11LatVelo0 1024;
BA_ "GenSigSendType" SG_ 330 FLR2RdrObject10To11LatVelo1 1;
BA_ "GenSigStartValue" SG_ 330 FLR2RdrObject10To11LatVelo1 1024;
BA_ "GenSigSendType" SG_ 330 FLR2RdrObject10To11LgtAcc0 1;
BA_ "GenSigStartValue" SG_ 330 FLR2RdrObject10To11LgtAcc0 356;
BA_ "GenSigSendType" SG_ 330 FLR2RdrObject10To11LgtAcc1 1;
BA_ "GenSigStartValue" SG_ 330 FLR2RdrObject10To11LgtAcc1 356;
BA_ "GenSigSendType" SG_ 330 FLR2RdrObject10To11LgtPos0 1;
BA_ "GenSigStartValue" SG_ 330 FLR2RdrObject10To11LgtPos0 4095;
BA_ "GenSigSendType" SG_ 330 FLR2RdrObject10To11LgtPos1 1;
BA_ "GenSigStartValue" SG_ 330 FLR2RdrObject10To11LgtPos1 4095;
BA_ "GenSigSendType" SG_ 330 FLR2RdrObject10To11LgtVelo0 1;
BA_ "GenSigStartValue" SG_ 330 FLR2RdrObject10To11LgtVelo0 1024;
BA_ "GenSigSendType" SG_ 330 FLR2RdrObject10To11LgtVelo1 1;
BA_ "GenSigStartValue" SG_ 330 FLR2RdrObject10To11LgtVelo1 1024;
BA_ "GenSigSendType" SG_ 330 FLR2RdrObject10To11ModeInfo0 1;
BA_ "GenSigSendType" SG_ 330 FLR2RdrObject10To11ModeInfo1 1;
BA_ "GenSigSendType" SG_ 330 FLR2RdrObject10To11MsgCntr 1;
BA_ "GenSigSendType" SG_ 330 FLR2RdrObject10To11MtnModel0 1;
BA_ "GenSigSendType" SG_ 330 FLR2RdrObject10To11MtnModel1 1;
BA_ "GenSigSendType" SG_ 330 FLR2RdrObject10To11MtnPattern0 1;
BA_ "GenSigSendType" SG_ 330 FLR2RdrObject10To11MtnPattern1 1;
BA_ "GenSigSendType" SG_ 330 FLR2RdrObject10To11PedMicroDoppler0 1;
BA_ "GenSigSendType" SG_ 330 FLR2RdrObject10To11PedMicroDoppler1 1;
BA_ "GenSigSendType" SG_ 330 FLR2RdrObject10To11Qly0 1;
BA_ "GenSigSendType" SG_ 330 FLR2RdrObject10To11Qly1 1;
BA_ "GenSigSendType" SG_ 330 FLR2RdrObject10To11ScanID 1;
BA_ "GenSigDataID" SG_ 332 FLR2RdrObject12To13CRC "0x8D4";
BA_ "GenSigFuncType" SG_ 332 FLR2RdrObject12To13CRC 28;
BA_ "GenSigSendType" SG_ 332 FLR2RdrObject12To13CRC 1;
BA_ "GenSigSendType" SG_ 332 FLR2RdrObject12To13Class0 1;
BA_ "GenSigSendType" SG_ 332 FLR2RdrObject12To13Class1 1;
BA_ "GenSigFuncType" SG_ 332 FLR2RdrObject12To13Counter 27;
BA_ "GenSigSendType" SG_ 332 FLR2RdrObject12To13Counter 1;
BA_ "GenSigSendType" SG_ 332 FLR2RdrObject12To13DataCoastCntr0 1;
BA_ "GenSigSendType" SG_ 332 FLR2RdrObject12To13DataCoastCntr1 1;
BA_ "GenSigSendType" SG_ 332 FLR2RdrObject12To13DataConf0 1;
BA_ "GenSigSendType" SG_ 332 FLR2RdrObject12To13DataConf1 1;
BA_ "GenSigSendType" SG_ 332 FLR2RdrObject12To13DataLen0 1;
BA_ "GenSigSendType" SG_ 332 FLR2RdrObject12To13DataLen1 1;
BA_ "GenSigSendType" SG_ 332 FLR2RdrObject12To13DataStDLatAcc0 1;
BA_ "GenSigSendType" SG_ 332 FLR2RdrObject12To13DataStDLatAcc1 1;
BA_ "GenSigSendType" SG_ 332 FLR2RdrObject12To13DataStDLatPos0 1;
BA_ "GenSigSendType" SG_ 332 FLR2RdrObject12To13DataStDLatPos1 1;
BA_ "GenSigSendType" SG_ 332 FLR2RdrObject12To13DataStDLatVelo0 1;
BA_ "GenSigSendType" SG_ 332 FLR2RdrObject12To13DataStDLatVelo1 1;
BA_ "GenSigSendType" SG_ 332 FLR2RdrObject12To13DataStDLgtAcc0 1;
BA_ "GenSigSendType" SG_ 332 FLR2RdrObject12To13DataStDLgtAcc1 1;
BA_ "GenSigSendType" SG_ 332 FLR2RdrObject12To13DataStDLgtPos0 1;
BA_ "GenSigSendType" SG_ 332 FLR2RdrObject12To13DataStDLgtPos1 1;
BA_ "GenSigSendType" SG_ 332 FLR2RdrObject12To13DataStDLgtVelo0 1;
BA_ "GenSigSendType" SG_ 332 FLR2RdrObject12To13DataStDLgtVelo1 1;
BA_ "GenSigSendType" SG_ 332 FLR2RdrObject12To13DataWidth0 1;
BA_ "GenSigSendType" SG_ 332 FLR2RdrObject12To13DataWidth1 1;
BA_ "GenSigSendType" SG_ 332 FLR2RdrObject12To13HeadingAng0 1;
BA_ "GenSigStartValue" SG_ 332 FLR2RdrObject12To13HeadingAng0 315;
BA_ "GenSigSendType" SG_ 332 FLR2RdrObject12To13HeadingAng1 1;
BA_ "GenSigStartValue" SG_ 332 FLR2RdrObject12To13HeadingAng1 315;
BA_ "GenSigSendType" SG_ 332 FLR2RdrObject12To13LatAcc0 1;
BA_ "GenSigStartValue" SG_ 332 FLR2RdrObject12To13LatAcc0 356;
BA_ "GenSigSendType" SG_ 332 FLR2RdrObject12To13LatAcc1 1;
BA_ "GenSigStartValue" SG_ 332 FLR2RdrObject12To13LatAcc1 356;
BA_ "GenSigSendType" SG_ 332 FLR2RdrObject12To13LatPos0 1;
BA_ "GenSigStartValue" SG_ 332 FLR2RdrObject12To13LatPos0 4095;
BA_ "GenSigSendType" SG_ 332 FLR2RdrObject12To13LatPos1 1;
BA_ "GenSigStartValue" SG_ 332 FLR2RdrObject12To13LatPos1 4095;
BA_ "GenSigSendType" SG_ 332 FLR2RdrObject12To13LatVelo0 1;
BA_ "GenSigStartValue" SG_ 332 FLR2RdrObject12To13LatVelo0 1024;
BA_ "GenSigSendType" SG_ 332 FLR2RdrObject12To13LatVelo1 1;
BA_ "GenSigStartValue" SG_ 332 FLR2RdrObject12To13LatVelo1 1024;
BA_ "GenSigSendType" SG_ 332 FLR2RdrObject12To13LgtAcc0 1;
BA_ "GenSigStartValue" SG_ 332 FLR2RdrObject12To13LgtAcc0 356;
BA_ "GenSigSendType" SG_ 332 FLR2RdrObject12To13LgtAcc1 1;
BA_ "GenSigStartValue" SG_ 332 FLR2RdrObject12To13LgtAcc1 356;
BA_ "GenSigSendType" SG_ 332 FLR2RdrObject12To13LgtPos0 1;
BA_ "GenSigStartValue" SG_ 332 FLR2RdrObject12To13LgtPos0 4095;
BA_ "GenSigSendType" SG_ 332 FLR2RdrObject12To13LgtPos1 1;
BA_ "GenSigStartValue" SG_ 332 FLR2RdrObject12To13LgtPos1 4095;
BA_ "GenSigSendType" SG_ 332 FLR2RdrObject12To13LgtVelo0 1;
BA_ "GenSigStartValue" SG_ 332 FLR2RdrObject12To13LgtVelo0 1024;
BA_ "GenSigSendType" SG_ 332 FLR2RdrObject12To13LgtVelo1 1;
BA_ "GenSigStartValue" SG_ 332 FLR2RdrObject12To13LgtVelo1 1024;
BA_ "GenSigSendType" SG_ 332 FLR2RdrObject12To13ModeInfo0 1;
BA_ "GenSigSendType" SG_ 332 FLR2RdrObject12To13ModeInfo1 1;
BA_ "GenSigSendType" SG_ 332 FLR2RdrObject12To13MsgCntr 1;
BA_ "GenSigSendType" SG_ 332 FLR2RdrObject12To13MtnModel0 1;
BA_ "GenSigSendType" SG_ 332 FLR2RdrObject12To13MtnModel1 1;
BA_ "GenSigSendType" SG_ 332 FLR2RdrObject12To13MtnPattern0 1;
BA_ "GenSigSendType" SG_ 332 FLR2RdrObject12To13MtnPattern1 1;
BA_ "GenSigSendType" SG_ 332 FLR2RdrObject12To13PedMicroDoppler0 1;
BA_ "GenSigSendType" SG_ 332 FLR2RdrObject12To13PedMicroDoppler1 1;
BA_ "GenSigSendType" SG_ 332 FLR2RdrObject12To13Qly0 1;
BA_ "GenSigSendType" SG_ 332 FLR2RdrObject12To13Qly1 1;
BA_ "GenSigSendType" SG_ 332 FLR2RdrObject12To13ScanID 1;
BA_ "GenSigDataID" SG_ 322 FLR2RdrObject2To3CRC "0x8CF";
BA_ "GenSigFuncType" SG_ 322 FLR2RdrObject2To3CRC 28;
BA_ "GenSigSendType" SG_ 322 FLR2RdrObject2To3CRC 1;
BA_ "GenSigSendType" SG_ 322 FLR2RdrObject2To3Class0 1;
BA_ "GenSigSendType" SG_ 322 FLR2RdrObject2To3Class1 1;
BA_ "GenSigFuncType" SG_ 322 FLR2RdrObject2To3Counter 27;
BA_ "GenSigSendType" SG_ 322 FLR2RdrObject2To3Counter 1;
BA_ "GenSigSendType" SG_ 322 FLR2RdrObject2To3DataCoastCntr0 1;
BA_ "GenSigSendType" SG_ 322 FLR2RdrObject2To3DataCoastCntr1 1;
BA_ "GenSigSendType" SG_ 322 FLR2RdrObject2To3DataConf0 1;
BA_ "GenSigSendType" SG_ 322 FLR2RdrObject2To3DataConf1 1;
BA_ "GenSigSendType" SG_ 322 FLR2RdrObject2To3DataLen0 1;
BA_ "GenSigSendType" SG_ 322 FLR2RdrObject2To3DataLen1 1;
BA_ "GenSigSendType" SG_ 322 FLR2RdrObject2To3DataStDLatAcc0 1;
BA_ "GenSigSendType" SG_ 322 FLR2RdrObject2To3DataStDLatAcc1 1;
BA_ "GenSigSendType" SG_ 322 FLR2RdrObject2To3DataStDLatPos0 1;
BA_ "GenSigSendType" SG_ 322 FLR2RdrObject2To3DataStDLatPos1 1;
BA_ "GenSigSendType" SG_ 322 FLR2RdrObject2To3DataStDLatVelo0 1;
BA_ "GenSigSendType" SG_ 322 FLR2RdrObject2To3DataStDLatVelo1 1;
BA_ "GenSigSendType" SG_ 322 FLR2RdrObject2To3DataStDLgtAcc0 1;
BA_ "GenSigSendType" SG_ 322 FLR2RdrObject2To3DataStDLgtAcc1 1;
BA_ "GenSigSendType" SG_ 322 FLR2RdrObject2To3DataStDLgtPos0 1;
BA_ "GenSigSendType" SG_ 322 FLR2RdrObject2To3DataStDLgtPos1 1;
BA_ "GenSigSendType" SG_ 322 FLR2RdrObject2To3DataStDLgtVelo0 1;
BA_ "GenSigSendType" SG_ 322 FLR2RdrObject2To3DataStDLgtVelo1 1;
BA_ "GenSigSendType" SG_ 322 FLR2RdrObject2To3DataWidth0 1;
BA_ "GenSigSendType" SG_ 322 FLR2RdrObject2To3DataWidth1 1;
BA_ "GenSigSendType" SG_ 322 FLR2RdrObject2To3HeadingAng0 1;
BA_ "GenSigStartValue" SG_ 322 FLR2RdrObject2To3HeadingAng0 315;
BA_ "GenSigSendType" SG_ 322 FLR2RdrObject2To3HeadingAng1 1;
BA_ "GenSigStartValue" SG_ 322 FLR2RdrObject2To3HeadingAng1 315;
BA_ "GenSigSendType" SG_ 322 FLR2RdrObject2To3LatAcc0 1;
BA_ "GenSigStartValue" SG_ 322 FLR2RdrObject2To3LatAcc0 356;
BA_ "GenSigSendType" SG_ 322 FLR2RdrObject2To3LatAcc1 1;
BA_ "GenSigStartValue" SG_ 322 FLR2RdrObject2To3LatAcc1 356;
BA_ "GenSigSendType" SG_ 322 FLR2RdrObject2To3LatPos0 1;
BA_ "GenSigStartValue" SG_ 322 FLR2RdrObject2To3LatPos0 4095;
BA_ "GenSigSendType" SG_ 322 FLR2RdrObject2To3LatPos1 1;
BA_ "GenSigStartValue" SG_ 322 FLR2RdrObject2To3LatPos1 4095;
BA_ "GenSigSendType" SG_ 322 FLR2RdrObject2To3LatVelo0 1;
BA_ "GenSigStartValue" SG_ 322 FLR2RdrObject2To3LatVelo0 1024;
BA_ "GenSigSendType" SG_ 322 FLR2RdrObject2To3LatVelo1 1;
BA_ "GenSigStartValue" SG_ 322 FLR2RdrObject2To3LatVelo1 1024;
BA_ "GenSigSendType" SG_ 322 FLR2RdrObject2To3LgtAcc0 1;
BA_ "GenSigStartValue" SG_ 322 FLR2RdrObject2To3LgtAcc0 356;
BA_ "GenSigSendType" SG_ 322 FLR2RdrObject2To3LgtAcc1 1;
BA_ "GenSigStartValue" SG_ 322 FLR2RdrObject2To3LgtAcc1 356;
BA_ "GenSigSendType" SG_ 322 FLR2RdrObject2To3LgtPos0 1;
BA_ "GenSigStartValue" SG_ 322 FLR2RdrObject2To3LgtPos0 4095;
BA_ "GenSigSendType" SG_ 322 FLR2RdrObject2To3LgtPos1 1;
BA_ "GenSigStartValue" SG_ 322 FLR2RdrObject2To3LgtPos1 4095;
BA_ "GenSigSendType" SG_ 322 FLR2RdrObject2To3LgtVelo0 1;
BA_ "GenSigStartValue" SG_ 322 FLR2RdrObject2To3LgtVelo0 1024;
BA_ "GenSigSendType" SG_ 322 FLR2RdrObject2To3LgtVelo1 1;
BA_ "GenSigStartValue" SG_ 322 FLR2RdrObject2To3LgtVelo1 1024;
BA_ "GenSigSendType" SG_ 322 FLR2RdrObject2To3ModeInfo0 1;
BA_ "GenSigSendType" SG_ 322 FLR2RdrObject2To3ModeInfo1 1;
BA_ "GenSigSendType" SG_ 322 FLR2RdrObject2To3MsgCntr 1;
BA_ "GenSigSendType" SG_ 322 FLR2RdrObject2To3MtnModel0 1;
BA_ "GenSigSendType" SG_ 322 FLR2RdrObject2To3MtnModel1 1;
BA_ "GenSigSendType" SG_ 322 FLR2RdrObject2To3MtnPattern0 1;
BA_ "GenSigSendType" SG_ 322 FLR2RdrObject2To3MtnPattern1 1;
BA_ "GenSigSendType" SG_ 322 FLR2RdrObject2To3PedMicroDoppler0 1;
BA_ "GenSigSendType" SG_ 322 FLR2RdrObject2To3PedMicroDoppler1 1;
BA_ "GenSigSendType" SG_ 322 FLR2RdrObject2To3Qly0 1;
BA_ "GenSigSendType" SG_ 322 FLR2RdrObject2To3Qly1 1;
BA_ "GenSigSendType" SG_ 322 FLR2RdrObject2To3ScanID 1;
BA_ "GenSigDataID" SG_ 324 FLR2RdrObject4To5CRC "0x8D0";
BA_ "GenSigFuncType" SG_ 324 FLR2RdrObject4To5CRC 28;
BA_ "GenSigSendType" SG_ 324 FLR2RdrObject4To5CRC 1;
BA_ "GenSigSendType" SG_ 324 FLR2RdrObject4To5Class0 1;
BA_ "GenSigSendType" SG_ 324 FLR2RdrObject4To5Class1 1;
BA_ "GenSigFuncType" SG_ 324 FLR2RdrObject4To5Counter 27;
BA_ "GenSigSendType" SG_ 324 FLR2RdrObject4To5Counter 1;
BA_ "GenSigSendType" SG_ 324 FLR2RdrObject4To5DataCoastCntr0 1;
BA_ "GenSigSendType" SG_ 324 FLR2RdrObject4To5DataCoastCntr1 1;
BA_ "GenSigSendType" SG_ 324 FLR2RdrObject4To5DataConf0 1;
BA_ "GenSigSendType" SG_ 324 FLR2RdrObject4To5DataConf1 1;
BA_ "GenSigSendType" SG_ 324 FLR2RdrObject4To5DataLen0 1;
BA_ "GenSigSendType" SG_ 324 FLR2RdrObject4To5DataLen1 1;
BA_ "GenSigSendType" SG_ 324 FLR2RdrObject4To5DataStDLatAcc0 1;
BA_ "GenSigSendType" SG_ 324 FLR2RdrObject4To5DataStDLatAcc1 1;
BA_ "GenSigSendType" SG_ 324 FLR2RdrObject4To5DataStDLatPos0 1;
BA_ "GenSigSendType" SG_ 324 FLR2RdrObject4To5DataStDLatPos1 1;
BA_ "GenSigSendType" SG_ 324 FLR2RdrObject4To5DataStDLatVelo0 1;
BA_ "GenSigSendType" SG_ 324 FLR2RdrObject4To5DataStDLatVelo1 1;
BA_ "GenSigSendType" SG_ 324 FLR2RdrObject4To5DataStDLgtAcc0 1;
BA_ "GenSigSendType" SG_ 324 FLR2RdrObject4To5DataStDLgtAcc1 1;
BA_ "GenSigSendType" SG_ 324 FLR2RdrObject4To5DataStDLgtPos0 1;
BA_ "GenSigSendType" SG_ 324 FLR2RdrObject4To5DataStDLgtPos1 1;
BA_ "GenSigSendType" SG_ 324 FLR2RdrObject4To5DataStDLgtVelo0 1;
BA_ "GenSigSendType" SG_ 324 FLR2RdrObject4To5DataStDLgtVelo1 1;
BA_ "GenSigSendType" SG_ 324 FLR2RdrObject4To5DataWidth0 1;
BA_ "GenSigSendType" SG_ 324 FLR2RdrObject4To5DataWidth1 1;
BA_ "GenSigSendType" SG_ 324 FLR2RdrObject4To5HeadingAng0 1;
BA_ "GenSigStartValue" SG_ 324 FLR2RdrObject4To5HeadingAng0 315;
BA_ "GenSigSendType" SG_ 324 FLR2RdrObject4To5HeadingAng1 1;
BA_ "GenSigStartValue" SG_ 324 FLR2RdrObject4To5HeadingAng1 315;
BA_ "GenSigSendType" SG_ 324 FLR2RdrObject4To5LatAcc0 1;
BA_ "GenSigStartValue" SG_ 324 FLR2RdrObject4To5LatAcc0 356;
BA_ "GenSigSendType" SG_ 324 FLR2RdrObject4To5LatAcc1 1;
BA_ "GenSigStartValue" SG_ 324 FLR2RdrObject4To5LatAcc1 356;
BA_ "GenSigSendType" SG_ 324 FLR2RdrObject4To5LatPos0 1;
BA_ "GenSigStartValue" SG_ 324 FLR2RdrObject4To5LatPos0 4095;
BA_ "GenSigSendType" SG_ 324 FLR2RdrObject4To5LatPos1 1;
BA_ "GenSigStartValue" SG_ 324 FLR2RdrObject4To5LatPos1 4095;
BA_ "GenSigSendType" SG_ 324 FLR2RdrObject4To5LatVelo0 1;
BA_ "GenSigStartValue" SG_ 324 FLR2RdrObject4To5LatVelo0 1024;
BA_ "GenSigSendType" SG_ 324 FLR2RdrObject4To5LatVelo1 1;
BA_ "GenSigStartValue" SG_ 324 FLR2RdrObject4To5LatVelo1 1024;
BA_ "GenSigSendType" SG_ 324 FLR2RdrObject4To5LgtAcc0 1;
BA_ "GenSigStartValue" SG_ 324 FLR2RdrObject4To5LgtAcc0 356;
BA_ "GenSigSendType" SG_ 324 FLR2RdrObject4To5LgtAcc1 1;
BA_ "GenSigStartValue" SG_ 324 FLR2RdrObject4To5LgtAcc1 356;
BA_ "GenSigSendType" SG_ 324 FLR2RdrObject4To5LgtPos0 1;
BA_ "GenSigStartValue" SG_ 324 FLR2RdrObject4To5LgtPos0 4095;
BA_ "GenSigSendType" SG_ 324 FLR2RdrObject4To5LgtPos1 1;
BA_ "GenSigStartValue" SG_ 324 FLR2RdrObject4To5LgtPos1 4095;
BA_ "GenSigSendType" SG_ 324 FLR2RdrObject4To5LgtVelo0 1;
BA_ "GenSigStartValue" SG_ 324 FLR2RdrObject4To5LgtVelo0 1024;
BA_ "GenSigSendType" SG_ 324 FLR2RdrObject4To5LgtVelo1 1;
BA_ "GenSigStartValue" SG_ 324 FLR2RdrObject4To5LgtVelo1 1024;
BA_ "GenSigSendType" SG_ 324 FLR2RdrObject4To5ModeInfo0 1;
BA_ "GenSigSendType" SG_ 324 FLR2RdrObject4To5ModeInfo1 1;
BA_ "GenSigSendType" SG_ 324 FLR2RdrObject4To5MsgCntr 1;
BA_ "GenSigSendType" SG_ 324 FLR2RdrObject4To5MtnModel0 1;
BA_ "GenSigSendType" SG_ 324 FLR2RdrObject4To5MtnModel1 1;
BA_ "GenSigSendType" SG_ 324 FLR2RdrObject4To5MtnPattern0 1;
BA_ "GenSigSendType" SG_ 324 FLR2RdrObject4To5MtnPattern1 1;
BA_ "GenSigSendType" SG_ 324 FLR2RdrObject4To5PedMicroDoppler0 1;
BA_ "GenSigSendType" SG_ 324 FLR2RdrObject4To5PedMicroDoppler1 1;
BA_ "GenSigSendType" SG_ 324 FLR2RdrObject4To5Qly0 1;
BA_ "GenSigSendType" SG_ 324 FLR2RdrObject4To5Qly1 1;
BA_ "GenSigSendType" SG_ 324 FLR2RdrObject4To5ScanID 1;
BA_ "GenSigDataID" SG_ 326 FLR2RdrObject6To7CRC "0x8D1";
BA_ "GenSigFuncType" SG_ 326 FLR2RdrObject6To7CRC 28;
BA_ "GenSigSendType" SG_ 326 FLR2RdrObject6To7CRC 1;
BA_ "GenSigSendType" SG_ 326 FLR2RdrObject6To7Class0 1;
BA_ "GenSigSendType" SG_ 326 FLR2RdrObject6To7Class1 1;
BA_ "GenSigFuncType" SG_ 326 FLR2RdrObject6To7Counter 27;
BA_ "GenSigSendType" SG_ 326 FLR2RdrObject6To7Counter 1;
BA_ "GenSigSendType" SG_ 326 FLR2RdrObject6To7DataCoastCntr0 1;
BA_ "GenSigSendType" SG_ 326 FLR2RdrObject6To7DataCoastCntr1 1;
BA_ "GenSigSendType" SG_ 326 FLR2RdrObject6To7DataConf0 1;
BA_ "GenSigSendType" SG_ 326 FLR2RdrObject6To7DataConf1 1;
BA_ "GenSigSendType" SG_ 326 FLR2RdrObject6To7DataLen0 1;
BA_ "GenSigSendType" SG_ 326 FLR2RdrObject6To7DataLen1 1;
BA_ "GenSigSendType" SG_ 326 FLR2RdrObject6To7DataStDLatAcc0 1;
BA_ "GenSigSendType" SG_ 326 FLR2RdrObject6To7DataStDLatAcc1 1;
BA_ "GenSigSendType" SG_ 326 FLR2RdrObject6To7DataStDLatPos0 1;
BA_ "GenSigSendType" SG_ 326 FLR2RdrObject6To7DataStDLatPos1 1;
BA_ "GenSigSendType" SG_ 326 FLR2RdrObject6To7DataStDLatVelo0 1;
BA_ "GenSigSendType" SG_ 326 FLR2RdrObject6To7DataStDLatVelo1 1;
BA_ "GenSigSendType" SG_ 326 FLR2RdrObject6To7DataStDLgtAcc0 1;
BA_ "GenSigSendType" SG_ 326 FLR2RdrObject6To7DataStDLgtAcc1 1;
BA_ "GenSigSendType" SG_ 326 FLR2RdrObject6To7DataStDLgtPos0 1;
BA_ "GenSigSendType" SG_ 326 FLR2RdrObject6To7DataStDLgtPos1 1;
BA_ "GenSigSendType" SG_ 326 FLR2RdrObject6To7DataStDLgtVelo0 1;
BA_ "GenSigSendType" SG_ 326 FLR2RdrObject6To7DataStDLgtVelo1 1;
BA_ "GenSigSendType" SG_ 326 FLR2RdrObject6To7DataWidth0 1;
BA_ "GenSigSendType" SG_ 326 FLR2RdrObject6To7DataWidth1 1;
BA_ "GenSigSendType" SG_ 326 FLR2RdrObject6To7HeadingAng0 1;
BA_ "GenSigStartValue" SG_ 326 FLR2RdrObject6To7HeadingAng0 315;
BA_ "GenSigSendType" SG_ 326 FLR2RdrObject6To7HeadingAng1 1;
BA_ "GenSigStartValue" SG_ 326 FLR2RdrObject6To7HeadingAng1 315;
BA_ "GenSigSendType" SG_ 326 FLR2RdrObject6To7LatAcc0 1;
BA_ "GenSigStartValue" SG_ 326 FLR2RdrObject6To7LatAcc0 356;
BA_ "GenSigSendType" SG_ 326 FLR2RdrObject6To7LatAcc1 1;
BA_ "GenSigStartValue" SG_ 326 FLR2RdrObject6To7LatAcc1 356;
BA_ "GenSigSendType" SG_ 326 FLR2RdrObject6To7LatPos0 1;
BA_ "GenSigStartValue" SG_ 326 FLR2RdrObject6To7LatPos0 4095;
BA_ "GenSigSendType" SG_ 326 FLR2RdrObject6To7LatPos1 1;
BA_ "GenSigStartValue" SG_ 326 FLR2RdrObject6To7LatPos1 4095;
BA_ "GenSigSendType" SG_ 326 FLR2RdrObject6To7LatVelo0 1;
BA_ "GenSigStartValue" SG_ 326 FLR2RdrObject6To7LatVelo0 1024;
BA_ "GenSigSendType" SG_ 326 FLR2RdrObject6To7LatVelo1 1;
BA_ "GenSigStartValue" SG_ 326 FLR2RdrObject6To7LatVelo1 1024;
BA_ "GenSigSendType" SG_ 326 FLR2RdrObject6To7LgtAcc0 1;
BA_ "GenSigStartValue" SG_ 326 FLR2RdrObject6To7LgtAcc0 356;
BA_ "GenSigSendType" SG_ 326 FLR2RdrObject6To7LgtAcc1 1;
BA_ "GenSigStartValue" SG_ 326 FLR2RdrObject6To7LgtAcc1 356;
BA_ "GenSigSendType" SG_ 326 FLR2RdrObject6To7LgtPos0 1;
BA_ "GenSigStartValue" SG_ 326 FLR2RdrObject6To7LgtPos0 4095;
BA_ "GenSigSendType" SG_ 326 FLR2RdrObject6To7LgtPos1 1;
BA_ "GenSigStartValue" SG_ 326 FLR2RdrObject6To7LgtPos1 4095;
BA_ "GenSigSendType" SG_ 326 FLR2RdrObject6To7LgtVelo0 1;
BA_ "GenSigStartValue" SG_ 326 FLR2RdrObject6To7LgtVelo0 1024;
BA_ "GenSigSendType" SG_ 326 FLR2RdrObject6To7LgtVelo1 1;
BA_ "GenSigStartValue" SG_ 326 FLR2RdrObject6To7LgtVelo1 1024;
BA_ "GenSigSendType" SG_ 326 FLR2RdrObject6To7ModeInfo0 1;
BA_ "GenSigSendType" SG_ 326 FLR2RdrObject6To7ModeInfo1 1;
BA_ "GenSigSendType" SG_ 326 FLR2RdrObject6To7MsgCntr 1;
BA_ "GenSigSendType" SG_ 326 FLR2RdrObject6To7MtnModel0 1;
BA_ "GenSigSendType" SG_ 326 FLR2RdrObject6To7MtnModel1 1;
BA_ "GenSigSendType" SG_ 326 FLR2RdrObject6To7MtnPattern0 1;
BA_ "GenSigSendType" SG_ 326 FLR2RdrObject6To7MtnPattern1 1;
BA_ "GenSigSendType" SG_ 326 FLR2RdrObject6To7PedMicroDoppler0 1;
BA_ "GenSigSendType" SG_ 326 FLR2RdrObject6To7PedMicroDoppler1 1;
BA_ "GenSigSendType" SG_ 326 FLR2RdrObject6To7Qly0 1;
BA_ "GenSigSendType" SG_ 326 FLR2RdrObject6To7Qly1 1;
BA_ "GenSigSendType" SG_ 326 FLR2RdrObject6To7ScanID 1;
BA_ "GenSigDataID" SG_ 328 FLR2RdrObject8To9CRC "0x8D2";
BA_ "GenSigFuncType" SG_ 328 FLR2RdrObject8To9CRC 28;
BA_ "GenSigSendType" SG_ 328 FLR2RdrObject8To9CRC 1;
BA_ "GenSigSendType" SG_ 328 FLR2RdrObject8To9Class0 1;
BA_ "GenSigSendType" SG_ 328 FLR2RdrObject8To9Class1 1;
BA_ "GenSigFuncType" SG_ 328 FLR2RdrObject8To9Counter 27;
BA_ "GenSigSendType" SG_ 328 FLR2RdrObject8To9Counter 1;
BA_ "GenSigSendType" SG_ 328 FLR2RdrObject8To9DataCoastCntr0 1;
BA_ "GenSigSendType" SG_ 328 FLR2RdrObject8To9DataCoastCntr1 1;
BA_ "GenSigSendType" SG_ 328 FLR2RdrObject8To9DataConf0 1;
BA_ "GenSigSendType" SG_ 328 FLR2RdrObject8To9DataConf1 1;
BA_ "GenSigSendType" SG_ 328 FLR2RdrObject8To9DataLen0 1;
BA_ "GenSigSendType" SG_ 328 FLR2RdrObject8To9DataLen1 1;
BA_ "GenSigSendType" SG_ 328 FLR2RdrObject8To9DataStDLatAcc0 1;
BA_ "GenSigSendType" SG_ 328 FLR2RdrObject8To9DataStDLatAcc1 1;
BA_ "GenSigSendType" SG_ 328 FLR2RdrObject8To9DataStDLatPos0 1;
BA_ "GenSigSendType" SG_ 328 FLR2RdrObject8To9DataStDLatPos1 1;
BA_ "GenSigSendType" SG_ 328 FLR2RdrObject8To9DataStDLatVelo0 1;
BA_ "GenSigSendType" SG_ 328 FLR2RdrObject8To9DataStDLatVelo1 1;
BA_ "GenSigSendType" SG_ 328 FLR2RdrObject8To9DataStDLgtAcc0 1;
BA_ "GenSigSendType" SG_ 328 FLR2RdrObject8To9DataStDLgtAcc1 1;
BA_ "GenSigSendType" SG_ 328 FLR2RdrObject8To9DataStDLgtPos0 1;
BA_ "GenSigSendType" SG_ 328 FLR2RdrObject8To9DataStDLgtPos1 1;
BA_ "GenSigSendType" SG_ 328 FLR2RdrObject8To9DataStDLgtVelo0 1;
BA_ "GenSigSendType" SG_ 328 FLR2RdrObject8To9DataStDLgtVelo1 1;
BA_ "GenSigSendType" SG_ 328 FLR2RdrObject8To9DataWidth0 1;
BA_ "GenSigSendType" SG_ 328 FLR2RdrObject8To9DataWidth1 1;
BA_ "GenSigSendType" SG_ 328 FLR2RdrObject8To9HeadingAng0 1;
BA_ "GenSigStartValue" SG_ 328 FLR2RdrObject8To9HeadingAng0 315;
BA_ "GenSigSendType" SG_ 328 FLR2RdrObject8To9HeadingAng1 1;
BA_ "GenSigStartValue" SG_ 328 FLR2RdrObject8To9HeadingAng1 315;
BA_ "GenSigSendType" SG_ 328 FLR2RdrObject8To9LatAcc0 1;
BA_ "GenSigStartValue" SG_ 328 FLR2RdrObject8To9LatAcc0 356;
BA_ "GenSigSendType" SG_ 328 FLR2RdrObject8To9LatAcc1 1;
BA_ "GenSigStartValue" SG_ 328 FLR2RdrObject8To9LatAcc1 356;
BA_ "GenSigSendType" SG_ 328 FLR2RdrObject8To9LatPos0 1;
BA_ "GenSigStartValue" SG_ 328 FLR2RdrObject8To9LatPos0 4095;
BA_ "GenSigSendType" SG_ 328 FLR2RdrObject8To9LatPos1 1;
BA_ "GenSigStartValue" SG_ 328 FLR2RdrObject8To9LatPos1 4095;
BA_ "GenSigSendType" SG_ 328 FLR2RdrObject8To9LatVelo0 1;
BA_ "GenSigStartValue" SG_ 328 FLR2RdrObject8To9LatVelo0 1024;
BA_ "GenSigSendType" SG_ 328 FLR2RdrObject8To9LatVelo1 1;
BA_ "GenSigStartValue" SG_ 328 FLR2RdrObject8To9LatVelo1 1024;
BA_ "GenSigSendType" SG_ 328 FLR2RdrObject8To9LgtAcc0 1;
BA_ "GenSigStartValue" SG_ 328 FLR2RdrObject8To9LgtAcc0 356;
BA_ "GenSigSendType" SG_ 328 FLR2RdrObject8To9LgtAcc1 1;
BA_ "GenSigStartValue" SG_ 328 FLR2RdrObject8To9LgtAcc1 356;
BA_ "GenSigSendType" SG_ 328 FLR2RdrObject8To9LgtPos0 1;
BA_ "GenSigStartValue" SG_ 328 FLR2RdrObject8To9LgtPos0 4095;
BA_ "GenSigSendType" SG_ 328 FLR2RdrObject8To9LgtPos1 1;
BA_ "GenSigStartValue" SG_ 328 FLR2RdrObject8To9LgtPos1 4095;
BA_ "GenSigSendType" SG_ 328 FLR2RdrObject8To9LgtVelo0 1;
BA_ "GenSigStartValue" SG_ 328 FLR2RdrObject8To9LgtVelo0 1024;
BA_ "GenSigSendType" SG_ 328 FLR2RdrObject8To9LgtVelo1 1;
BA_ "GenSigStartValue" SG_ 328 FLR2RdrObject8To9LgtVelo1 1024;
BA_ "GenSigSendType" SG_ 328 FLR2RdrObject8To9ModeInfo0 1;
BA_ "GenSigSendType" SG_ 328 FLR2RdrObject8To9ModeInfo1 1;
BA_ "GenSigSendType" SG_ 328 FLR2RdrObject8To9MsgCntr 1;
BA_ "GenSigSendType" SG_ 328 FLR2RdrObject8To9MtnModel0 1;
BA_ "GenSigSendType" SG_ 328 FLR2RdrObject8To9MtnModel1 1;
BA_ "GenSigSendType" SG_ 328 FLR2RdrObject8To9MtnPattern0 1;
BA_ "GenSigSendType" SG_ 328 FLR2RdrObject8To9MtnPattern1 1;
BA_ "GenSigSendType" SG_ 328 FLR2RdrObject8To9PedMicroDoppler0 1;
BA_ "GenSigSendType" SG_ 328 FLR2RdrObject8To9PedMicroDoppler1 1;
BA_ "GenSigSendType" SG_ 328 FLR2RdrObject8To9Qly0 1;
BA_ "GenSigSendType" SG_ 328 FLR2RdrObject8To9Qly1 1;
BA_ "GenSigSendType" SG_ 328 FLR2RdrObject8To9ScanID 1;
BA_ "GenSigSendType" SG_ 576 FuncInfoAntilockBrakingSystemState 0;
BA_ "GenSigSendType" SG_ 576 FuncInfoBrkTracCtrlActv 0;
BA_ "GenSigDataID" SG_ 576 FuncInfoCRC "0xB7A";
BA_ "GenSigFuncType" SG_ 576 FuncInfoCRC 28;
BA_ "GenSigSendType" SG_ 576 FuncInfoCRC 0;
BA_ "GenSigFuncType" SG_ 576 FuncInfoCounter 27;
BA_ "GenSigSendType" SG_ 576 FuncInfoCounter 0;
BA_ "GenSigDataID" SG_ 544 GlobalSnapShotRdrCRC "0xD1C";
BA_ "GenSigFuncType" SG_ 544 GlobalSnapShotRdrCRC 28;
BA_ "GenSigSendType" SG_ 544 GlobalSnapShotRdrCRC 0;
BA_ "GenSigFuncType" SG_ 544 GlobalSnapShotRdrCounter 27;
BA_ "GenSigSendType" SG_ 544 GlobalSnapShotRdrCounter 0;
BA_ "GenSigSendType" SG_ 544 GlobalSnapShotRdrGlobalRealTimeRdr 0;
BA_ "GenSigStartValue" SG_ 544 GlobalSnapShotRdrGlobalRealTimeRdr 4294967295;
BA_ "GenSigSendType" SG_ 544 GlobalSnapShotRdrOutsideTemperatureRdr 0;
BA_ "GenSigStartValue" SG_ 544 GlobalSnapShotRdrOutsideTemperatureRdr -32768;
BA_ "GenSigSendType" SG_ 544 GlobalSnapShotRdrTotalDistanceRdr 0;
BA_ "GenSigStartValue" SG_ 544 GlobalSnapShotRdrTotalDistanceRdr 4294967295;
BA_ "GenSigSendType" SG_ 544 GlobalSnapShotRdrUsageModeRdr 0;
BA_ "GenSigSendType" SG_ 544 GlobalSnapShotRdrVehicleBatteryVoltageRdr 0;
BA_ "GenSigStartValue" SG_ 544 GlobalSnapShotRdrVehicleBatteryVoltageRdr 255;
BA_ "GenSigSendType" SG_ 544 GlobalSnapShotRdrVehicleSpeedRdr 0;
BA_ "GenSigStartValue" SG_ 544 GlobalSnapShotRdrVehicleSpeedRdr 255;
BA_ "GenSigDataID" SG_ 528 PowerModeFLRCRC "0xD0B";
BA_ "GenSigFuncType" SG_ 528 PowerModeFLRCRC 28;
BA_ "GenSigSendType" SG_ 528 PowerModeFLRCRC 0;
BA_ "GenSigFuncType" SG_ 528 PowerModeFLRCounter 27;
BA_ "GenSigSendType" SG_ 528 PowerModeFLRCounter 0;
BA_ "GenSigSendType" SG_ 528 PowerModeFLRRdrActvnReq 0;
BA_ "GenSigSendType" SG_ 528 PowerModeFLRRdrPwrlossNoti 0;
BA_ "GenSigDataID" SG_ 560 VehicleModesProviderCRC "0xA47";
BA_ "GenSigFuncType" SG_ 560 VehicleModesProviderCRC 28;
BA_ "GenSigSendType" SG_ 560 VehicleModesProviderCRC 0;
BA_ "GenSigSendType" SG_ 560 VehicleModesProviderCarModSts 0;
BA_ "GenSigSendType" SG_ 560 VehicleModesProviderCarModSubtypWd 0;
BA_ "GenSigFuncType" SG_ 560 VehicleModesProviderCounter 27;
BA_ "GenSigSendType" SG_ 560 VehicleModesProviderCounter 0;
BA_ "GenSigSendType" SG_ 560 VehicleModesProviderUsageModeAvailable 0;
BA_ "GenSigStartValue" SG_ 560 VehicleModesProviderUsageModeAvailable 1;
BA_ "GenSigSendType" SG_ 560 VehicleModesProviderUsageModeAwake 0;
BA_ "GenSigStartValue" SG_ 560 VehicleModesProviderUsageModeAwake 1;
BA_ "GenSigSendType" SG_ 560 VehicleModesProviderUsageModeConvenience 0;
BA_ "GenSigStartValue" SG_ 560 VehicleModesProviderUsageModeConvenience 1;
BA_ "GenSigSendType" SG_ 560 VehicleModesProviderUsageModeDriving 0;
BA_ "GenSigStartValue" SG_ 560 VehicleModesProviderUsageModeDriving 1;
BA_ "GenSigSendType" SG_ 560 VehicleModesProviderUsageModeMovable 0;
BA_ "GenSigStartValue" SG_ 560 VehicleModesProviderUsageModeMovable 1;
BA_ "GenSigSendType" SG_ 560 VehicleModesProviderUsageModeResponsive 0;
BA_ "GenSigStartValue" SG_ 560 VehicleModesProviderUsageModeResponsive 1;
BA_ "GenSigSendType" SG_ 512 VehicleMotionStateAcceleroMeterLateral 0;
BA_ "GenSigStartValue" SG_ 512 VehicleMotionStateAcceleroMeterLateral 16352;
BA_ "GenSigSendType" SG_ 512 VehicleMotionStateAccelerometerLateralQuality 0;
BA_ "GenSigStartValue" SG_ 512 VehicleMotionStateAccelerometerLateralQuality 1;
BA_ "GenSigSendType" SG_ 512 VehicleMotionStateAccelerometerLongitudinal 0;
BA_ "GenSigStartValue" SG_ 512 VehicleMotionStateAccelerometerLongitudinal 16352;
BA_ "GenSigSendType" SG_ 512 VehicleMotionStateAccelerometerLongitudinalQuality 0;
BA_ "GenSigStartValue" SG_ 512 VehicleMotionStateAccelerometerLongitudinalQuality 1;
BA_ "GenSigSendType" SG_ 512 VehicleMotionStateAccelerometerVertical 0;
BA_ "GenSigStartValue" SG_ 512 VehicleMotionStateAccelerometerVertical 16352;
BA_ "GenSigSendType" SG_ 512 VehicleMotionStateAccelerometerVerticalQuality 0;
BA_ "GenSigStartValue" SG_ 512 VehicleMotionStateAccelerometerVerticalQuality 1;
BA_ "GenSigSendType" SG_ 512 VehicleMotionStateAngularVelocityRoll 0;
BA_ "GenSigStartValue" SG_ 512 VehicleMotionStateAngularVelocityRoll 32768;
BA_ "GenSigSendType" SG_ 512 VehicleMotionStateAngularVelocityRollQuality 0;
BA_ "GenSigStartValue" SG_ 512 VehicleMotionStateAngularVelocityRollQuality 1;
BA_ "GenSigSendType" SG_ 512 VehicleMotionStateAngularVelocityYaw 0;
BA_ "GenSigStartValue" SG_ 512 VehicleMotionStateAngularVelocityYaw 32768;
BA_ "GenSigSendType" SG_ 512 VehicleMotionStateAngularVelocityYawQuality 0;
BA_ "GenSigStartValue" SG_ 512 VehicleMotionStateAngularVelocityYawQuality 1;
BA_ "GenSigDataID" SG_ 512 VehicleMotionStateCRC "0xA33";
BA_ "GenSigFuncType" SG_ 512 VehicleMotionStateCRC 28;
BA_ "GenSigSendType" SG_ 512 VehicleMotionStateCRC 0;
BA_ "GenSigFuncType" SG_ 512 VehicleMotionStateCounter 27;
BA_ "GenSigSendType" SG_ 512 VehicleMotionStateCounter 0;
BA_ "GenSigSendType" SG_ 512 VehicleMotionStateMovingDirection 0;
BA_ "GenSigSendType" SG_ 512 VehicleMotionStateMovingDirectionQuality 0;
BA_ "GenSigStartValue" SG_ 512 VehicleMotionStateMovingDirectionQuality 1;
BA_ "GenSigSendType" SG_ 512 VehicleMotionStateVelocityLongitudinal 0;
BA_ "GenSigSendType" SG_ 512 VehicleMotionStateVelocityLongitudinalQuality 0;
BA_ "GenSigStartValue" SG_ 512 VehicleMotionStateVelocityLongitudinalQuality 1;
BA_ "GenSigSendType" SG_ 512 VehicleMotionStateWheelAngle 0;
BA_ "GenSigStartValue" SG_ 512 VehicleMotionStateWheelAngle 32386.9994285;
BA_ "GenSigSendType" SG_ 512 VehicleMotionStateWheelAngleQuality 0;
BA_ "GenSigStartValue" SG_ 512 VehicleMotionStateWheelAngleQuality 1;
BA_ "GenSigSendType" SG_ 512 VehicleMotionStateWheelAngularVelocityFrontLeft 0;
BA_ "GenSigStartValue" SG_ 512 VehicleMotionStateWheelAngularVelocityFrontLeft 32640;
BA_ "GenSigSendType" SG_ 512 VehicleMotionStateWheelAngularVelocityFrontLeftQuality 0;
BA_ "GenSigStartValue" SG_ 512 VehicleMotionStateWheelAngularVelocityFrontLeftQuality 1;
BA_ "GenSigSendType" SG_ 512 VehicleMotionStateWheelAngularVelocityFrontRight 0;
BA_ "GenSigStartValue" SG_ 512 VehicleMotionStateWheelAngularVelocityFrontRight 32640;
BA_ "GenSigSendType" SG_ 512 VehicleMotionStateWheelAngularVelocityFrontRightQuality 0;
BA_ "GenSigStartValue" SG_ 512 VehicleMotionStateWheelAngularVelocityFrontRightQuality 1;
BA_ "GenSigSendType" SG_ 512 VehicleMotionStateWheelAngularVelocityRearLeft 0;
BA_ "GenSigStartValue" SG_ 512 VehicleMotionStateWheelAngularVelocityRearLeft 32640;
BA_ "GenSigSendType" SG_ 512 VehicleMotionStateWheelAngularVelocityRearLeftQuality 0;
BA_ "GenSigStartValue" SG_ 512 VehicleMotionStateWheelAngularVelocityRearLeftQuality 1;
BA_ "GenSigSendType" SG_ 512 VehicleMotionStateWheelAngularVelocityRearRight 0;
BA_ "GenSigStartValue" SG_ 512 VehicleMotionStateWheelAngularVelocityRearRight 32640;
BA_ "GenSigSendType" SG_ 512 VehicleMotionStateWheelAngularVelocityRearRightQuality 0;
BA_ "GenSigStartValue" SG_ 512 VehicleMotionStateWheelAngularVelocityRearRightQuality 1;

VAL_ 512 VehicleMotionStateAccelerometerLateralQuality 0 "QualityOfEstimate_Error" 1 "QualityOfEstimate_Unknown" 2 "QualityOfEstimate_Low" 3 "QualityOfEstimate_Medium" 4 "QualityOfEstimate_High" 5 "QualityOfEstimate_Full";
VAL_ 512 VehicleMotionStateAccelerometerLongitudinalQuality 0 "QualityOfEstimate_Error" 1 "QualityOfEstimate_Unknown" 2 "QualityOfEstimate_Low" 3 "QualityOfEstimate_Medium" 4 "QualityOfEstimate_High" 5 "QualityOfEstimate_Full";
VAL_ 512 VehicleMotionStateAccelerometerVerticalQuality 0 "QualityOfEstimate_Error" 1 "QualityOfEstimate_Unknown" 2 "QualityOfEstimate_Low" 3 "QualityOfEstimate_Medium" 4 "QualityOfEstimate_High" 5 "QualityOfEstimate_Full";
VAL_ 512 VehicleMotionStateAngularVelocityRollQuality 0 "QualityOfEstimate_Error" 1 "QualityOfEstimate_Unknown" 2 "QualityOfEstimate_Low" 3 "QualityOfEstimate_Medium" 4 "QualityOfEstimate_High" 5 "QualityOfEstimate_Full";
VAL_ 512 VehicleMotionStateAngularVelocityYawQuality 0 "QualityOfEstimate_Error" 1 "QualityOfEstimate_Unknown" 2 "QualityOfEstimate_Low" 3 "QualityOfEstimate_Medium" 4 "QualityOfEstimate_High" 5 "QualityOfEstimate_Full";
VAL_ 512 VehicleMotionStateMovingDirection 0 "MovingDirection_Unknown" 1 "MovingDirection_Standstill" 2 "MovingDirection_NotStandstill" 3 "MovingDirection_Reverse" 4 "MovingDirection_Forward";
VAL_ 512 VehicleMotionStateMovingDirectionQuality 0 "QualityOfEstimate_Error" 1 "QualityOfEstimate_Unknown" 2 "QualityOfEstimate_Low" 3 "QualityOfEstimate_Medium" 4 "QualityOfEstimate_High" 5 "QualityOfEstimate_Full";
VAL_ 512 VehicleMotionStateVelocityLongitudinalQuality 0 "QualityOfEstimate_Error" 1 "QualityOfEstimate_Unknown" 2 "QualityOfEstimate_Low" 3 "QualityOfEstimate_Medium" 4 "QualityOfEstimate_High" 5 "QualityOfEstimate_Full";
VAL_ 512 VehicleMotionStateWheelAngleQuality 0 "QualityOfEstimate_Error" 1 "QualityOfEstimate_Unknown" 2 "QualityOfEstimate_Low" 3 "QualityOfEstimate_Medium" 4 "QualityOfEstimate_High" 5 "QualityOfEstimate_Full";
VAL_ 512 VehicleMotionStateWheelAngularVelocityFrontLeftQuality 0 "QualityOfEstimate_Error" 1 "QualityOfEstimate_Unknown" 2 "QualityOfEstimate_Low" 3 "QualityOfEstimate_Medium" 4 "QualityOfEstimate_High" 5 "QualityOfEstimate_Full";
VAL_ 512 VehicleMotionStateWheelAngularVelocityFrontRightQuality 0 "QualityOfEstimate_Error" 1 "QualityOfEstimate_Unknown" 2 "QualityOfEstimate_Low" 3 "QualityOfEstimate_Medium" 4 "QualityOfEstimate_High" 5 "QualityOfEstimate_Full";
VAL_ 512 VehicleMotionStateWheelAngularVelocityRearLeftQuality 0 "QualityOfEstimate_Error" 1 "QualityOfEstimate_Unknown" 2 "QualityOfEstimate_Low" 3 "QualityOfEstimate_Medium" 4 "QualityOfEstimate_High" 5 "QualityOfEstimate_Full";
VAL_ 512 VehicleMotionStateWheelAngularVelocityRearRightQuality 0 "QualityOfEstimate_Error" 1 "QualityOfEstimate_Unknown" 2 "QualityOfEstimate_Low" 3 "QualityOfEstimate_Medium" 4 "QualityOfEstimate_High" 5 "QualityOfEstimate_Full";
VAL_ 528 CarConfigPropulsionType 0 "PropulsionTyp_Unknown" 1 "PropulsionTyp_BatteryElectricVehicle" 2 "PropulsionTyp_HybridVehicle";
VAL_ 528 CarConfigVehicleTyp 0 "VehicleTyp_Unknown" 1 "VehicleTyp_P519" 2 "VehicleTyp_V536" 4 "VehicleTyp_P61A" 5 "VehicleTyp_V551";
VAL_ 528 PowerModeFLRRdrActvnReq 0 "RdrActvnReq_Off" 1 "RdrActvnReq_On";
VAL_ 528 PowerModeFLRRdrPwrlossNoti 0 "RdrPwrlossNoti_NoPwrLoss" 1 "RdrPwrlossNoti_PwrLoss";
VAL_ 560 VehicleModesProviderCarModSts 0 "RdrCarModSts_Normal" 1 "RdrCarModSts_Transport" 2 "RdrCarModSts_Factory" 3 "RdrCarModSts_Dyno" 4 "RdrCarModSts_Show" 5 "RdrCarModSts_Crash";
VAL_ 560 VehicleModesProviderCarModSubtypWd 0 "CarModSubtypWd_Normal" 1 "CarModSubtypWd_FactoryPaused" 2 "CarModSubtypWd_FactoryDriving" 3 "CarModSubtypWd_TransportDriving" 4 "CarModSubtypWd_TwoWheelDyno" 5 "CarModSubtypWd_FourWheelDyno";
VAL_ 560 VehicleModesProviderUsageModeAvailable 0 "UsgMod_False" 1 "UsgMod_True";
VAL_ 560 VehicleModesProviderUsageModeAwake 0 "UsgMod_False" 1 "UsgMod_True";
VAL_ 560 VehicleModesProviderUsageModeConvenience 0 "UsgMod_False" 1 "UsgMod_True";
VAL_ 560 VehicleModesProviderUsageModeDriving 0 "UsgMod_False" 1 "UsgMod_True";
VAL_ 560 VehicleModesProviderUsageModeMovable 0 "UsgMod_False" 1 "UsgMod_True";
VAL_ 560 VehicleModesProviderUsageModeResponsive 0 "UsgMod_False" 1 "UsgMod_True";
VAL_ 576 FuncInfoAntilockBrakingSystemState 0 "AbsState_disable" 1 "AbsState_enable";
VAL_ 576 FuncInfoBrkTracCtrlActv 0 "BrkTracCtrlActv_inactive" 1 "BrkTracCtrlActv_active";
VAL_ 320 FLR2RdrObject0To1Class0 0 "FLR2ObjectClassification2_Unknown" 1 "FLR2ObjectClassification2_MotVeh" 2 "FLR2ObjectClassification2_Bicycle" 3 "FLR2ObjectClassification2_Ped";
VAL_ 320 FLR2RdrObject0To1Class1 0 "FLR2ObjectClassification2_Unknown" 1 "FLR2ObjectClassification2_MotVeh" 2 "FLR2ObjectClassification2_Bicycle" 3 "FLR2ObjectClassification2_Ped";
VAL_ 320 FLR2RdrObject0To1DataCoastCntr0 0 "FLR2ObjDataCoastingCntr_DeletedMaintainanceState" 1 "FLR2ObjDataCoastingCntr_NewMaintainanceState" 2 "FLR2ObjDataCoastingCntr_MeasuredMaintainanceState" 3 "FLR2ObjDataCoastingCntr_PredictedMaintainanceState";
VAL_ 320 FLR2RdrObject0To1DataCoastCntr1 0 "FLR2ObjDataCoastingCntr_DeletedMaintainanceState" 1 "FLR2ObjDataCoastingCntr_NewMaintainanceState" 2 "FLR2ObjDataCoastingCntr_MeasuredMaintainanceState" 3 "FLR2ObjDataCoastingCntr_PredictedMaintainanceState";
VAL_ 320 FLR2RdrObject0To1ModeInfo0 0 "FLR2Modeinfo_RngNearResl" 1 "FLR2Modeinfo_RngMidReslMod" 2 "FLR2Modeinfo_RngLongReslMod";
VAL_ 320 FLR2RdrObject0To1ModeInfo1 0 "FLR2Modeinfo_RngNearResl" 1 "FLR2Modeinfo_RngMidReslMod" 2 "FLR2Modeinfo_RngLongReslMod";
VAL_ 320 FLR2RdrObject0To1MtnPattern0 0 "FLR2MotionPattern_Movg" 1 "FLR2MotionPattern_Staty" 2 "FLR2MotionPattern_OnCmgn" 3 "FLR2MotionPattern_MovgLeToRi" 4 "FLR2MotionPattern_MovgRiToLe" 5 "FLR2MotionPattern_UkwnToRadarSnsr" 6 "FLR2MotionPattern_Stop" 7 "FLR2MotionPattern_StopNotSafe";
VAL_ 320 FLR2RdrObject0To1MtnPattern1 0 "FLR2MotionPattern_Movg" 1 "FLR2MotionPattern_Staty" 2 "FLR2MotionPattern_OnCmgn" 3 "FLR2MotionPattern_MovgLeToRi" 4 "FLR2MotionPattern_MovgRiToLe" 5 "FLR2MotionPattern_UkwnToRadarSnsr" 6 "FLR2MotionPattern_Stop" 7 "FLR2MotionPattern_StopNotSafe";
VAL_ 322 FLR2RdrObject2To3Class0 0 "FLR2ObjectClassification2_Unknown" 1 "FLR2ObjectClassification2_MotVeh" 2 "FLR2ObjectClassification2_Bicycle" 3 "FLR2ObjectClassification2_Ped";
VAL_ 322 FLR2RdrObject2To3Class1 0 "FLR2ObjectClassification2_Unknown" 1 "FLR2ObjectClassification2_MotVeh" 2 "FLR2ObjectClassification2_Bicycle" 3 "FLR2ObjectClassification2_Ped";
VAL_ 322 FLR2RdrObject2To3DataCoastCntr0 0 "FLR2ObjDataCoastingCntr_DeletedMaintainanceState" 1 "FLR2ObjDataCoastingCntr_NewMaintainanceState" 2 "FLR2ObjDataCoastingCntr_MeasuredMaintainanceState" 3 "FLR2ObjDataCoastingCntr_PredictedMaintainanceState";
VAL_ 322 FLR2RdrObject2To3DataCoastCntr1 0 "FLR2ObjDataCoastingCntr_DeletedMaintainanceState" 1 "FLR2ObjDataCoastingCntr_NewMaintainanceState" 2 "FLR2ObjDataCoastingCntr_MeasuredMaintainanceState" 3 "FLR2ObjDataCoastingCntr_PredictedMaintainanceState";
VAL_ 322 FLR2RdrObject2To3ModeInfo0 0 "FLR2Modeinfo_RngNearResl" 1 "FLR2Modeinfo_RngMidReslMod" 2 "FLR2Modeinfo_RngLongReslMod";
VAL_ 322 FLR2RdrObject2To3ModeInfo1 0 "FLR2Modeinfo_RngNearResl" 1 "FLR2Modeinfo_RngMidReslMod" 2 "FLR2Modeinfo_RngLongReslMod";
VAL_ 322 FLR2RdrObject2To3MtnPattern0 0 "FLR2MotionPattern_Movg" 1 "FLR2MotionPattern_Staty" 2 "FLR2MotionPattern_OnCmgn" 3 "FLR2MotionPattern_MovgLeToRi" 4 "FLR2MotionPattern_MovgRiToLe" 5 "FLR2MotionPattern_UkwnToRadarSnsr" 6 "FLR2MotionPattern_Stop" 7 "FLR2MotionPattern_StopNotSafe";
VAL_ 322 FLR2RdrObject2To3MtnPattern1 0 "FLR2MotionPattern_Movg" 1 "FLR2MotionPattern_Staty" 2 "FLR2MotionPattern_OnCmgn" 3 "FLR2MotionPattern_MovgLeToRi" 4 "FLR2MotionPattern_MovgRiToLe" 5 "FLR2MotionPattern_UkwnToRadarSnsr" 6 "FLR2MotionPattern_Stop" 7 "FLR2MotionPattern_StopNotSafe";
VAL_ 324 FLR2RdrObject4To5Class0 0 "FLR2ObjectClassification2_Unknown" 1 "FLR2ObjectClassification2_MotVeh" 2 "FLR2ObjectClassification2_Bicycle" 3 "FLR2ObjectClassification2_Ped";
VAL_ 324 FLR2RdrObject4To5Class1 0 "FLR2ObjectClassification2_Unknown" 1 "FLR2ObjectClassification2_MotVeh" 2 "FLR2ObjectClassification2_Bicycle" 3 "FLR2ObjectClassification2_Ped";
VAL_ 324 FLR2RdrObject4To5DataCoastCntr0 0 "FLR2ObjDataCoastingCntr_DeletedMaintainanceState" 1 "FLR2ObjDataCoastingCntr_NewMaintainanceState" 2 "FLR2ObjDataCoastingCntr_MeasuredMaintainanceState" 3 "FLR2ObjDataCoastingCntr_PredictedMaintainanceState";
VAL_ 324 FLR2RdrObject4To5DataCoastCntr1 0 "FLR2ObjDataCoastingCntr_DeletedMaintainanceState" 1 "FLR2ObjDataCoastingCntr_NewMaintainanceState" 2 "FLR2ObjDataCoastingCntr_MeasuredMaintainanceState" 3 "FLR2ObjDataCoastingCntr_PredictedMaintainanceState";
VAL_ 324 FLR2RdrObject4To5ModeInfo0 0 "FLR2Modeinfo_RngNearResl" 1 "FLR2Modeinfo_RngMidReslMod" 2 "FLR2Modeinfo_RngLongReslMod";
VAL_ 324 FLR2RdrObject4To5ModeInfo1 0 "FLR2Modeinfo_RngNearResl" 1 "FLR2Modeinfo_RngMidReslMod" 2 "FLR2Modeinfo_RngLongReslMod";
VAL_ 324 FLR2RdrObject4To5MtnPattern0 0 "FLR2MotionPattern_Movg" 1 "FLR2MotionPattern_Staty" 2 "FLR2MotionPattern_OnCmgn" 3 "FLR2MotionPattern_MovgLeToRi" 4 "FLR2MotionPattern_MovgRiToLe" 5 "FLR2MotionPattern_UkwnToRadarSnsr" 6 "FLR2MotionPattern_Stop" 7 "FLR2MotionPattern_StopNotSafe";
VAL_ 324 FLR2RdrObject4To5MtnPattern1 0 "FLR2MotionPattern_Movg" 1 "FLR2MotionPattern_Staty" 2 "FLR2MotionPattern_OnCmgn" 3 "FLR2MotionPattern_MovgLeToRi" 4 "FLR2MotionPattern_MovgRiToLe" 5 "FLR2MotionPattern_UkwnToRadarSnsr" 6 "FLR2MotionPattern_Stop" 7 "FLR2MotionPattern_StopNotSafe";
VAL_ 326 FLR2RdrObject6To7Class0 0 "FLR2ObjectClassification2_Unknown" 1 "FLR2ObjectClassification2_MotVeh" 2 "FLR2ObjectClassification2_Bicycle" 3 "FLR2ObjectClassification2_Ped";
VAL_ 326 FLR2RdrObject6To7Class1 0 "FLR2ObjectClassification2_Unknown" 1 "FLR2ObjectClassification2_MotVeh" 2 "FLR2ObjectClassification2_Bicycle" 3 "FLR2ObjectClassification2_Ped";
VAL_ 326 FLR2RdrObject6To7DataCoastCntr0 0 "FLR2ObjDataCoastingCntr_DeletedMaintainanceState" 1 "FLR2ObjDataCoastingCntr_NewMaintainanceState" 2 "FLR2ObjDataCoastingCntr_MeasuredMaintainanceState" 3 "FLR2ObjDataCoastingCntr_PredictedMaintainanceState";
VAL_ 326 FLR2RdrObject6To7DataCoastCntr1 0 "FLR2ObjDataCoastingCntr_DeletedMaintainanceState" 1 "FLR2ObjDataCoastingCntr_NewMaintainanceState" 2 "FLR2ObjDataCoastingCntr_MeasuredMaintainanceState" 3 "FLR2ObjDataCoastingCntr_PredictedMaintainanceState";
VAL_ 326 FLR2RdrObject6To7ModeInfo0 0 "FLR2Modeinfo_RngNearResl" 1 "FLR2Modeinfo_RngMidReslMod" 2 "FLR2Modeinfo_RngLongReslMod";
VAL_ 326 FLR2RdrObject6To7ModeInfo1 0 "FLR2Modeinfo_RngNearResl" 1 "FLR2Modeinfo_RngMidReslMod" 2 "FLR2Modeinfo_RngLongReslMod";
VAL_ 326 FLR2RdrObject6To7MtnPattern0 0 "FLR2MotionPattern_Movg" 1 "FLR2MotionPattern_Staty" 2 "FLR2MotionPattern_OnCmgn" 3 "FLR2MotionPattern_MovgLeToRi" 4 "FLR2MotionPattern_MovgRiToLe" 5 "FLR2MotionPattern_UkwnToRadarSnsr" 6 "FLR2MotionPattern_Stop" 7 "FLR2MotionPattern_StopNotSafe";
VAL_ 326 FLR2RdrObject6To7MtnPattern1 0 "FLR2MotionPattern_Movg" 1 "FLR2MotionPattern_Staty" 2 "FLR2MotionPattern_OnCmgn" 3 "FLR2MotionPattern_MovgLeToRi" 4 "FLR2MotionPattern_MovgRiToLe" 5 "FLR2MotionPattern_UkwnToRadarSnsr" 6 "FLR2MotionPattern_Stop" 7 "FLR2MotionPattern_StopNotSafe";
VAL_ 328 FLR2RdrObject8To9Class0 0 "FLR2ObjectClassification2_Unknown" 1 "FLR2ObjectClassification2_MotVeh" 2 "FLR2ObjectClassification2_Bicycle" 3 "FLR2ObjectClassification2_Ped";
VAL_ 328 FLR2RdrObject8To9Class1 0 "FLR2ObjectClassification2_Unknown" 1 "FLR2ObjectClassification2_MotVeh" 2 "FLR2ObjectClassification2_Bicycle" 3 "FLR2ObjectClassification2_Ped";
VAL_ 328 FLR2RdrObject8To9DataCoastCntr0 0 "FLR2ObjDataCoastingCntr_DeletedMaintainanceState" 1 "FLR2ObjDataCoastingCntr_NewMaintainanceState" 2 "FLR2ObjDataCoastingCntr_MeasuredMaintainanceState" 3 "FLR2ObjDataCoastingCntr_PredictedMaintainanceState";
VAL_ 328 FLR2RdrObject8To9DataCoastCntr1 0 "FLR2ObjDataCoastingCntr_DeletedMaintainanceState" 1 "FLR2ObjDataCoastingCntr_NewMaintainanceState" 2 "FLR2ObjDataCoastingCntr_MeasuredMaintainanceState" 3 "FLR2ObjDataCoastingCntr_PredictedMaintainanceState";
VAL_ 328 FLR2RdrObject8To9ModeInfo0 0 "FLR2Modeinfo_RngNearResl" 1 "FLR2Modeinfo_RngMidReslMod" 2 "FLR2Modeinfo_RngLongReslMod";
VAL_ 328 FLR2RdrObject8To9ModeInfo1 0 "FLR2Modeinfo_RngNearResl" 1 "FLR2Modeinfo_RngMidReslMod" 2 "FLR2Modeinfo_RngLongReslMod";
VAL_ 328 FLR2RdrObject8To9MtnPattern0 0 "FLR2MotionPattern_Movg" 1 "FLR2MotionPattern_Staty" 2 "FLR2MotionPattern_OnCmgn" 3 "FLR2MotionPattern_MovgLeToRi" 4 "FLR2MotionPattern_MovgRiToLe" 5 "FLR2MotionPattern_UkwnToRadarSnsr" 6 "FLR2MotionPattern_Stop" 7 "FLR2MotionPattern_StopNotSafe";
VAL_ 328 FLR2RdrObject8To9MtnPattern1 0 "FLR2MotionPattern_Movg" 1 "FLR2MotionPattern_Staty" 2 "FLR2MotionPattern_OnCmgn" 3 "FLR2MotionPattern_MovgLeToRi" 4 "FLR2MotionPattern_MovgRiToLe" 5 "FLR2MotionPattern_UkwnToRadarSnsr" 6 "FLR2MotionPattern_Stop" 7 "FLR2MotionPattern_StopNotSafe";
VAL_ 330 FLR2RdrObject10To11Class0 0 "FLR2ObjectClassification2_Unknown" 1 "FLR2ObjectClassification2_MotVeh" 2 "FLR2ObjectClassification2_Bicycle" 3 "FLR2ObjectClassification2_Ped";
VAL_ 330 FLR2RdrObject10To11Class1 0 "FLR2ObjectClassification2_Unknown" 1 "FLR2ObjectClassification2_MotVeh" 2 "FLR2ObjectClassification2_Bicycle" 3 "FLR2ObjectClassification2_Ped";
VAL_ 330 FLR2RdrObject10To11DataCoastCntr0 0 "FLR2ObjDataCoastingCntr_DeletedMaintainanceState" 1 "FLR2ObjDataCoastingCntr_NewMaintainanceState" 2 "FLR2ObjDataCoastingCntr_MeasuredMaintainanceState" 3 "FLR2ObjDataCoastingCntr_PredictedMaintainanceState";
VAL_ 330 FLR2RdrObject10To11DataCoastCntr1 0 "FLR2ObjDataCoastingCntr_DeletedMaintainanceState" 1 "FLR2ObjDataCoastingCntr_NewMaintainanceState" 2 "FLR2ObjDataCoastingCntr_MeasuredMaintainanceState" 3 "FLR2ObjDataCoastingCntr_PredictedMaintainanceState";
VAL_ 330 FLR2RdrObject10To11ModeInfo0 0 "FLR2Modeinfo_RngNearResl" 1 "FLR2Modeinfo_RngMidReslMod" 2 "FLR2Modeinfo_RngLongReslMod";
VAL_ 330 FLR2RdrObject10To11ModeInfo1 0 "FLR2Modeinfo_RngNearResl" 1 "FLR2Modeinfo_RngMidReslMod" 2 "FLR2Modeinfo_RngLongReslMod";
VAL_ 330 FLR2RdrObject10To11MtnPattern0 0 "FLR2MotionPattern_Movg" 1 "FLR2MotionPattern_Staty" 2 "FLR2MotionPattern_OnCmgn" 3 "FLR2MotionPattern_MovgLeToRi" 4 "FLR2MotionPattern_MovgRiToLe" 5 "FLR2MotionPattern_UkwnToRadarSnsr" 6 "FLR2MotionPattern_Stop" 7 "FLR2MotionPattern_StopNotSafe";
VAL_ 330 FLR2RdrObject10To11MtnPattern1 0 "FLR2MotionPattern_Movg" 1 "FLR2MotionPattern_Staty" 2 "FLR2MotionPattern_OnCmgn" 3 "FLR2MotionPattern_MovgLeToRi" 4 "FLR2MotionPattern_MovgRiToLe" 5 "FLR2MotionPattern_UkwnToRadarSnsr" 6 "FLR2MotionPattern_Stop" 7 "FLR2MotionPattern_StopNotSafe";
VAL_ 332 FLR2RdrObject12To13Class0 0 "FLR2ObjectClassification2_Unknown" 1 "FLR2ObjectClassification2_MotVeh" 2 "FLR2ObjectClassification2_Bicycle" 3 "FLR2ObjectClassification2_Ped";
VAL_ 332 FLR2RdrObject12To13Class1 0 "FLR2ObjectClassification2_Unknown" 1 "FLR2ObjectClassification2_MotVeh" 2 "FLR2ObjectClassification2_Bicycle" 3 "FLR2ObjectClassification2_Ped";
VAL_ 332 FLR2RdrObject12To13DataCoastCntr0 0 "FLR2ObjDataCoastingCntr_DeletedMaintainanceState" 1 "FLR2ObjDataCoastingCntr_NewMaintainanceState" 2 "FLR2ObjDataCoastingCntr_MeasuredMaintainanceState" 3 "FLR2ObjDataCoastingCntr_PredictedMaintainanceState";
VAL_ 332 FLR2RdrObject12To13DataCoastCntr1 0 "FLR2ObjDataCoastingCntr_DeletedMaintainanceState" 1 "FLR2ObjDataCoastingCntr_NewMaintainanceState" 2 "FLR2ObjDataCoastingCntr_MeasuredMaintainanceState" 3 "FLR2ObjDataCoastingCntr_PredictedMaintainanceState";
VAL_ 332 FLR2RdrObject12To13ModeInfo0 0 "FLR2Modeinfo_RngNearResl" 1 "FLR2Modeinfo_RngMidReslMod" 2 "FLR2Modeinfo_RngLongReslMod";
VAL_ 332 FLR2RdrObject12To13ModeInfo1 0 "FLR2Modeinfo_RngNearResl" 1 "FLR2Modeinfo_RngMidReslMod" 2 "FLR2Modeinfo_RngLongReslMod";
VAL_ 332 FLR2RdrObject12To13MtnPattern0 0 "FLR2MotionPattern_Movg" 1 "FLR2MotionPattern_Staty" 2 "FLR2MotionPattern_OnCmgn" 3 "FLR2MotionPattern_MovgLeToRi" 4 "FLR2MotionPattern_MovgRiToLe" 5 "FLR2MotionPattern_UkwnToRadarSnsr" 6 "FLR2MotionPattern_Stop" 7 "FLR2MotionPattern_StopNotSafe";
VAL_ 332 FLR2RdrObject12To13MtnPattern1 0 "FLR2MotionPattern_Movg" 1 "FLR2MotionPattern_Staty" 2 "FLR2MotionPattern_OnCmgn" 3 "FLR2MotionPattern_MovgLeToRi" 4 "FLR2MotionPattern_MovgRiToLe" 5 "FLR2MotionPattern_UkwnToRadarSnsr" 6 "FLR2MotionPattern_Stop" 7 "FLR2MotionPattern_StopNotSafe";
SIG_GROUP_ 528 CarConfig 1 : CarConfigCounter CarConfigCRC CarConfigPropulsionType CarConfigVehicleTyp;
SIG_GROUP_ 320 FLR2RdrObject0To1 1 : FLR2RdrObject0To1Class0 FLR2RdrObject0To1Class1 FLR2RdrObject0To1Counter FLR2RdrObject0To1CRC FLR2RdrObject0To1DataCoastCntr0 FLR2RdrObject0To1DataCoastCntr1 FLR2RdrObject0To1DataConf0 FLR2RdrObject0To1DataConf1 FLR2RdrObject0To1DataLen0 FLR2RdrObject0To1DataLen1 FLR2RdrObject0To1DataStDLatAcc0 FLR2RdrObject0To1DataStDLatAcc1 FLR2RdrObject0To1DataStDLatPos0 FLR2RdrObject0To1DataStDLatPos1 FLR2RdrObject0To1DataStDLatVelo0 FLR2RdrObject0To1DataStDLatVelo1 FLR2RdrObject0To1DataStDLgtAcc0 FLR2RdrObject0To1DataStDLgtAcc1 FLR2RdrObject0To1DataStDLgtPos0 FLR2RdrObject0To1DataStDLgtPos1 FLR2RdrObject0To1DataStDLgtVelo0 FLR2RdrObject0To1DataStDLgtVelo1 FLR2RdrObject0To1DataWidth0 FLR2RdrObject0To1DataWidth1 FLR2RdrObject0To1HeadingAng0 FLR2RdrObject0To1HeadingAng1 FLR2RdrObject0To1LatAcc0 FLR2RdrObject0To1LatAcc1 FLR2RdrObject0To1LatPos0 FLR2RdrObject0To1LatPos1 FLR2RdrObject0To1LatVelo0 FLR2RdrObject0To1LatVelo1 FLR2RdrObject0To1LgtAcc0 FLR2RdrObject0To1LgtAcc1 FLR2RdrObject0To1LgtPos0 FLR2RdrObject0To1LgtPos1 FLR2RdrObject0To1LgtVelo0 FLR2RdrObject0To1LgtVelo1 FLR2RdrObject0To1ModeInfo0 FLR2RdrObject0To1ModeInfo1 FLR2RdrObject0To1MsgCntr FLR2RdrObject0To1MtnModel0 FLR2RdrObject0To1MtnModel1 FLR2RdrObject0To1MtnPattern0 FLR2RdrObject0To1MtnPattern1 FLR2RdrObject0To1PedMicroDoppler0 FLR2RdrObject0To1PedMicroDoppler1 FLR2RdrObject0To1Qly0 FLR2RdrObject0To1Qly1 FLR2RdrObject0To1ScanID;
SIG_GROUP_ 330 FLR2RdrObject10To11 1 : FLR2RdrObject10To11Class0 FLR2RdrObject10To11Class1 FLR2RdrObject10To11Counter FLR2RdrObject10To11CRC FLR2RdrObject10To11DataCoastCntr0 FLR2RdrObject10To11DataCoastCntr1 FLR2RdrObject10To11DataConf0 FLR2RdrObject10To11DataConf1 FLR2RdrObject10To11DataLen0 FLR2RdrObject10To11DataLen1 FLR2RdrObject10To11DataStDLatAcc0 FLR2RdrObject10To11DataStDLatAcc1 FLR2RdrObject10To11DataStDLatPos0 FLR2RdrObject10To11DataStDLatPos1 FLR2RdrObject10To11DataStDLatVelo0 FLR2RdrObject10To11DataStDLatVelo1 FLR2RdrObject10To11DataStDLgtAcc0 FLR2RdrObject10To11DataStDLgtAcc1 FLR2RdrObject10To11DataStDLgtPos0 FLR2RdrObject10To11DataStDLgtPos1 FLR2RdrObject10To11DataStDLgtVelo0 FLR2RdrObject10To11DataStDLgtVelo1 FLR2RdrObject10To11DataWidth0 FLR2RdrObject10To11DataWidth1 FLR2RdrObject10To11HeadingAng0 FLR2RdrObject10To11HeadingAng1 FLR2RdrObject10To11LatAcc0 FLR2RdrObject10To11LatAcc1 FLR2RdrObject10To11LatPos0 FLR2RdrObject10To11LatPos1 FLR2RdrObject10To11LatVelo0 FLR2RdrObject10To11LatVelo1 FLR2RdrObject10To11LgtAcc0 FLR2RdrObject10To11LgtAcc1 FLR2RdrObject10To11LgtPos0 FLR2RdrObject10To11LgtPos1 FLR2RdrObject10To11LgtVelo0 FLR2RdrObject10To11LgtVelo1 FLR2RdrObject10To11ModeInfo0 FLR2RdrObject10To11ModeInfo1 FLR2RdrObject10To11MsgCntr FLR2RdrObject10To11MtnModel0 FLR2RdrObject10To11MtnModel1 FLR2RdrObject10To11MtnPattern0 FLR2RdrObject10To11MtnPattern1 FLR2RdrObject10To11PedMicroDoppler0 FLR2RdrObject10To11PedMicroDoppler1 FLR2RdrObject10To11Qly0 FLR2RdrObject10To11Qly1 FLR2RdrObject10To11ScanID;
SIG_GROUP_ 332 FLR2RdrObject12To13 1 : FLR2RdrObject12To13Class0 FLR2RdrObject12To13Class1 FLR2RdrObject12To13Counter FLR2RdrObject12To13CRC FLR2RdrObject12To13DataCoastCntr0 FLR2RdrObject12To13DataCoastCntr1 FLR2RdrObject12To13DataConf0 FLR2RdrObject12To13DataConf1 FLR2RdrObject12To13DataLen0 FLR2RdrObject12To13DataLen1 FLR2RdrObject12To13DataStDLatAcc0 FLR2RdrObject12To13DataStDLatAcc1 FLR2RdrObject12To13DataStDLatPos0 FLR2RdrObject12To13DataStDLatPos1 FLR2RdrObject12To13DataStDLatVelo0 FLR2RdrObject12To13DataStDLatVelo1 FLR2RdrObject12To13DataStDLgtAcc0 FLR2RdrObject12To13DataStDLgtAcc1 FLR2RdrObject12To13DataStDLgtPos0 FLR2RdrObject12To13DataStDLgtPos1 FLR2RdrObject12To13DataStDLgtVelo0 FLR2RdrObject12To13DataStDLgtVelo1 FLR2RdrObject12To13DataWidth0 FLR2RdrObject12To13DataWidth1 FLR2RdrObject12To13HeadingAng0 FLR2RdrObject12To13HeadingAng1 FLR2RdrObject12To13LatAcc0 FLR2RdrObject12To13LatAcc1 FLR2RdrObject12To13LatPos0 FLR2RdrObject12To13LatPos1 FLR2RdrObject12To13LatVelo0 FLR2RdrObject12To13LatVelo1 FLR2RdrObject12To13LgtAcc0 FLR2RdrObject12To13LgtAcc1 FLR2RdrObject12To13LgtPos0 FLR2RdrObject12To13LgtPos1 FLR2RdrObject12To13LgtVelo0 FLR2RdrObject12To13LgtVelo1 FLR2RdrObject12To13ModeInfo0 FLR2RdrObject12To13ModeInfo1 FLR2RdrObject12To13MsgCntr FLR2RdrObject12To13MtnModel0 FLR2RdrObject12To13MtnModel1 FLR2RdrObject12To13MtnPattern0 FLR2RdrObject12To13MtnPattern1 FLR2RdrObject12To13PedMicroDoppler0 FLR2RdrObject12To13PedMicroDoppler1 FLR2RdrObject12To13Qly0 FLR2RdrObject12To13Qly1 FLR2RdrObject12To13ScanID;
SIG_GROUP_ 322 FLR2RdrObject2To3 1 : FLR2RdrObject2To3Class0 FLR2RdrObject2To3Class1 FLR2RdrObject2To3Counter FLR2RdrObject2To3CRC FLR2RdrObject2To3DataCoastCntr0 FLR2RdrObject2To3DataCoastCntr1 FLR2RdrObject2To3DataConf0 FLR2RdrObject2To3DataConf1 FLR2RdrObject2To3DataLen0 FLR2RdrObject2To3DataLen1 FLR2RdrObject2To3DataStDLatAcc0 FLR2RdrObject2To3DataStDLatAcc1 FLR2RdrObject2To3DataStDLatPos0 FLR2RdrObject2To3DataStDLatPos1 FLR2RdrObject2To3DataStDLatVelo0 FLR2RdrObject2To3DataStDLatVelo1 FLR2RdrObject2To3DataStDLgtAcc0 FLR2RdrObject2To3DataStDLgtAcc1 FLR2RdrObject2To3DataStDLgtPos0 FLR2RdrObject2To3DataStDLgtPos1 FLR2RdrObject2To3DataStDLgtVelo0 FLR2RdrObject2To3DataStDLgtVelo1 FLR2RdrObject2To3DataWidth0 FLR2RdrObject2To3DataWidth1 FLR2RdrObject2To3HeadingAng0 FLR2RdrObject2To3HeadingAng1 FLR2RdrObject2To3LatAcc0 FLR2RdrObject2To3LatAcc1 FLR2RdrObject2To3LatPos0 FLR2RdrObject2To3LatPos1 FLR2RdrObject2To3LatVelo0 FLR2RdrObject2To3LatVelo1 FLR2RdrObject2To3LgtAcc0 FLR2RdrObject2To3LgtAcc1 FLR2RdrObject2To3LgtPos0 FLR2RdrObject2To3LgtPos1 FLR2RdrObject2To3LgtVelo0 FLR2RdrObject2To3LgtVelo1 FLR2RdrObject2To3ModeInfo0 FLR2RdrObject2To3ModeInfo1 FLR2RdrObject2To3MsgCntr FLR2RdrObject2To3MtnModel0 FLR2RdrObject2To3MtnModel1 FLR2RdrObject2To3MtnPattern0 FLR2RdrObject2To3MtnPattern1 FLR2RdrObject2To3PedMicroDoppler0 FLR2RdrObject2To3PedMicroDoppler1 FLR2RdrObject2To3Qly0 FLR2RdrObject2To3Qly1 FLR2RdrObject2To3ScanID;
SIG_GROUP_ 324 FLR2RdrObject4To5 1 : FLR2RdrObject4To5Class0 FLR2RdrObject4To5Class1 FLR2RdrObject4To5Counter FLR2RdrObject4To5CRC FLR2RdrObject4To5DataCoastCntr0 FLR2RdrObject4To5DataCoastCntr1 FLR2RdrObject4To5DataConf0 FLR2RdrObject4To5DataConf1 FLR2RdrObject4To5DataLen0 FLR2RdrObject4To5DataLen1 FLR2RdrObject4To5DataStDLatAcc0 FLR2RdrObject4To5DataStDLatAcc1 FLR2RdrObject4To5DataStDLatPos0 FLR2RdrObject4To5DataStDLatPos1 FLR2RdrObject4To5DataStDLatVelo0 FLR2RdrObject4To5DataStDLatVelo1 FLR2RdrObject4To5DataStDLgtAcc0 FLR2RdrObject4To5DataStDLgtAcc1 FLR2RdrObject4To5DataStDLgtPos0 FLR2RdrObject4To5DataStDLgtPos1 FLR2RdrObject4To5DataStDLgtVelo0 FLR2RdrObject4To5DataStDLgtVelo1 FLR2RdrObject4To5DataWidth0 FLR2RdrObject4To5DataWidth1 FLR2RdrObject4To5HeadingAng0 FLR2RdrObject4To5HeadingAng1 FLR2RdrObject4To5LatAcc0 FLR2RdrObject4To5LatAcc1 FLR2RdrObject4To5LatPos0 FLR2RdrObject4To5LatPos1 FLR2RdrObject4To5LatVelo0 FLR2RdrObject4To5LatVelo1 FLR2RdrObject4To5LgtAcc0 FLR2RdrObject4To5LgtAcc1 FLR2RdrObject4To5LgtPos0 FLR2RdrObject4To5LgtPos1 FLR2RdrObject4To5LgtVelo0 FLR2RdrObject4To5LgtVelo1 FLR2RdrObject4To5ModeInfo0 FLR2RdrObject4To5ModeInfo1 FLR2RdrObject4To5MsgCntr FLR2RdrObject4To5MtnModel0 FLR2RdrObject4To5MtnModel1 FLR2RdrObject4To5MtnPattern0 FLR2RdrObject4To5MtnPattern1 FLR2RdrObject4To5PedMicroDoppler0 FLR2RdrObject4To5PedMicroDoppler1 FLR2RdrObject4To5Qly0 FLR2RdrObject4To5Qly1 FLR2RdrObject4To5ScanID;
SIG_GROUP_ 326 FLR2RdrObject6To7 1 : FLR2RdrObject6To7Class0 FLR2RdrObject6To7Class1 FLR2RdrObject6To7Counter FLR2RdrObject6To7CRC FLR2RdrObject6To7DataCoastCntr0 FLR2RdrObject6To7DataCoastCntr1 FLR2RdrObject6To7DataConf0 FLR2RdrObject6To7DataConf1 FLR2RdrObject6To7DataLen0 FLR2RdrObject6To7DataLen1 FLR2RdrObject6To7DataStDLatAcc0 FLR2RdrObject6To7DataStDLatAcc1 FLR2RdrObject6To7DataStDLatPos0 FLR2RdrObject6To7DataStDLatPos1 FLR2RdrObject6To7DataStDLatVelo0 FLR2RdrObject6To7DataStDLatVelo1 FLR2RdrObject6To7DataStDLgtAcc0 FLR2RdrObject6To7DataStDLgtAcc1 FLR2RdrObject6To7DataStDLgtPos0 FLR2RdrObject6To7DataStDLgtPos1 FLR2RdrObject6To7DataStDLgtVelo0 FLR2RdrObject6To7DataStDLgtVelo1 FLR2RdrObject6To7DataWidth0 FLR2RdrObject6To7DataWidth1 FLR2RdrObject6To7HeadingAng0 FLR2RdrObject6To7HeadingAng1 FLR2RdrObject6To7LatAcc0 FLR2RdrObject6To7LatAcc1 FLR2RdrObject6To7LatPos0 FLR2RdrObject6To7LatPos1 FLR2RdrObject6To7LatVelo0 FLR2RdrObject6To7LatVelo1 FLR2RdrObject6To7LgtAcc0 FLR2RdrObject6To7LgtAcc1 FLR2RdrObject6To7LgtPos0 FLR2RdrObject6To7LgtPos1 FLR2RdrObject6To7LgtVelo0 FLR2RdrObject6To7LgtVelo1 FLR2RdrObject6To7ModeInfo0 FLR2RdrObject6To7ModeInfo1 FLR2RdrObject6To7MsgCntr FLR2RdrObject6To7MtnModel0 FLR2RdrObject6To7MtnModel1 FLR2RdrObject6To7MtnPattern0 FLR2RdrObject6To7MtnPattern1 FLR2RdrObject6To7PedMicroDoppler0 FLR2RdrObject6To7PedMicroDoppler1 FLR2RdrObject6To7Qly0 FLR2RdrObject6To7Qly1 FLR2RdrObject6To7ScanID;
SIG_GROUP_ 328 FLR2RdrObject8To9 1 : FLR2RdrObject8To9Class0 FLR2RdrObject8To9Class1 FLR2RdrObject8To9Counter FLR2RdrObject8To9CRC FLR2RdrObject8To9DataCoastCntr0 FLR2RdrObject8To9DataCoastCntr1 FLR2RdrObject8To9DataConf0 FLR2RdrObject8To9DataConf1 FLR2RdrObject8To9DataLen0 FLR2RdrObject8To9DataLen1 FLR2RdrObject8To9DataStDLatAcc0 FLR2RdrObject8To9DataStDLatAcc1 FLR2RdrObject8To9DataStDLatPos0 FLR2RdrObject8To9DataStDLatPos1 FLR2RdrObject8To9DataStDLatVelo0 FLR2RdrObject8To9DataStDLatVelo1 FLR2RdrObject8To9DataStDLgtAcc0 FLR2RdrObject8To9DataStDLgtAcc1 FLR2RdrObject8To9DataStDLgtPos0 FLR2RdrObject8To9DataStDLgtPos1 FLR2RdrObject8To9DataStDLgtVelo0 FLR2RdrObject8To9DataStDLgtVelo1 FLR2RdrObject8To9DataWidth0 FLR2RdrObject8To9DataWidth1 FLR2RdrObject8To9HeadingAng0 FLR2RdrObject8To9HeadingAng1 FLR2RdrObject8To9LatAcc0 FLR2RdrObject8To9LatAcc1 FLR2RdrObject8To9LatPos0 FLR2RdrObject8To9LatPos1 FLR2RdrObject8To9LatVelo0 FLR2RdrObject8To9LatVelo1 FLR2RdrObject8To9LgtAcc0 FLR2RdrObject8To9LgtAcc1 FLR2RdrObject8To9LgtPos0 FLR2RdrObject8To9LgtPos1 FLR2RdrObject8To9LgtVelo0 FLR2RdrObject8To9LgtVelo1 FLR2RdrObject8To9ModeInfo0 FLR2RdrObject8To9ModeInfo1 FLR2RdrObject8To9MsgCntr FLR2RdrObject8To9MtnModel0 FLR2RdrObject8To9MtnModel1 FLR2RdrObject8To9MtnPattern0 FLR2RdrObject8To9MtnPattern1 FLR2RdrObject8To9PedMicroDoppler0 FLR2RdrObject8To9PedMicroDoppler1 FLR2RdrObject8To9Qly0 FLR2RdrObject8To9Qly1 FLR2RdrObject8To9ScanID;
SIG_GROUP_ 576 FuncInfo 1 : FuncInfoAntilockBrakingSystemState FuncInfoBrkTracCtrlActv FuncInfoCounter FuncInfoCRC;
SIG_GROUP_ 544 GlobalSnapShotRdr 1 : GlobalSnapShotRdrCounter GlobalSnapShotRdrCRC GlobalSnapShotRdrGlobalRealTimeRdr GlobalSnapShotRdrOutsideTemperatureRdr GlobalSnapShotRdrTotalDistanceRdr GlobalSnapShotRdrUsageModeRdr GlobalSnapShotRdrVehicleBatteryVoltageRdr GlobalSnapShotRdrVehicleSpeedRdr;
SIG_GROUP_ 528 PowerModeFLR 1 : PowerModeFLRCounter PowerModeFLRCRC PowerModeFLRRdrActvnReq PowerModeFLRRdrPwrlossNoti;
SIG_GROUP_ 560 VehicleModesProvider 1 : VehicleModesProviderCarModSts VehicleModesProviderCarModSubtypWd VehicleModesProviderCounter VehicleModesProviderCRC VehicleModesProviderUsageModeAvailable VehicleModesProviderUsageModeAwake VehicleModesProviderUsageModeConvenience VehicleModesProviderUsageModeDriving VehicleModesProviderUsageModeMovable VehicleModesProviderUsageModeResponsive;
SIG_GROUP_ 512 VehicleMotionState 1 : VehicleMotionStateAcceleroMeterLateral VehicleMotionStateAccelerometerLateralQuality VehicleMotionStateAccelerometerLongitudinal VehicleMotionStateAccelerometerLongitudinalQuality VehicleMotionStateAccelerometerVertical VehicleMotionStateAccelerometerVerticalQuality VehicleMotionStateAngularVelocityRoll VehicleMotionStateAngularVelocityRollQuality VehicleMotionStateAngularVelocityYaw VehicleMotionStateAngularVelocityYawQuality VehicleMotionStateCounter VehicleMotionStateCRC VehicleMotionStateMovingDirection VehicleMotionStateMovingDirectionQuality VehicleMotionStateVelocityLongitudinal VehicleMotionStateVelocityLongitudinalQuality VehicleMotionStateWheelAngle VehicleMotionStateWheelAngleQuality VehicleMotionStateWheelAngularVelocityFrontLeft VehicleMotionStateWheelAngularVelocityFrontLeftQuality VehicleMotionStateWheelAngularVelocityFrontRight VehicleMotionStateWheelAngularVelocityFrontRightQuality VehicleMotionStateWheelAngularVelocityRearLeft VehicleMotionStateWheelAngularVelocityRearLeftQuality VehicleMotionStateWheelAngularVelocityRearRight VehicleMotionStateWheelAngularVelocityRearRightQuality;
